VERSION ""

NS_ :

BS_:

BU_: ACC SRS SMART NAVI AHU FCM EPS HDS SS30 METER CVT STR ENG ABS VSA
VAL_TABLE_ VSA_DTC_STORAGE_STATUS 1 "DTC Stored(History or Current)" 0 "DTC Not Stored" ;
VAL_TABLE_ VSA_ABS_DISABLE_EDR 1 "ABS故障中" ;
VAL_TABLE_ VSA_STABILITY_CTRL1_DISABLE_EDR 1 "STABILITY CONTROL1制御のうち、少なくとも１つ禁止しているとき" 0 "STABILITY CONTROL1制御のうち、すべて禁止していないとき" ;
VAL_TABLE_ VSA_STABILITY_CTRL2_DISABLE_EDR 1 "STABILITY CONTROL2制御のうち、少なくとも１つ禁止しているとき" 0 "STABILITY CONTROL2制御のうち、すべて禁止していないとき" ;
VAL_TABLE_ VSA_VSA_EQUIPPED_EDR 1 "VSA装備あり" 0 "VSA装備なし(ABS装備)" ;
VAL_TABLE_ VSA_ABS_ACT_EDR 1 "ABS作動中" ;
VAL_TABLE_ VSA_STABILITY_CTRL_ACT_EDR 1 "STABILITY CONTROL作動中" ;
VAL_TABLE_ VSA_VSA_OFF_STATUS_EDR 1 "VSA OFF 中" ;
VAL_TABLE_ VSA_L_MODE_ABS_EBD 1 "ABS,EBD L-MODE中" ;
VAL_TABLE_ ENG_STRNNEND 1 "完爆状態" ;
VAL_TABLE_ ENG_SW_STATUS_SCS 1 "SCSスイッチオン" ;
VAL_TABLE_ SS30_REQ_PREBRAKE 1 "予圧要求" ;
VAL_TABLE_ SS30_REQ_BRAKE 1 "減速要求" ;
VAL_TABLE_ SS30_REQ_BRAKEHOLD 1 "ブレーキ保持要求" ;
VAL_TABLE_ SS30_STATUS_FAIL 1 "SS30故障" ;
VAL_TABLE_ METER_SW_STATUS_PARK_BRAKE 1 "パーキングブレーキ スイッチ オン" ;
VAL_TABLE_ METER_SW_STATUS_BRAKE_FLUID 1 "ブレーキフルード レベル スイッチ オン" ;
VAL_TABLE_ METER_SW_STATUS_VSA_OFF 1 "VSA-オフ スイッチ オン  " ;
VAL_TABLE_ CVT_REFUSE_VSA_CONTROL 1 "VSA制御を拒絶するCVT故障発生中" ;
VAL_TABLE_ CVT_GEAR_POSITION_IND_CVT 15 "Lレンジ制御中" 8 "8th" 7 "7th" 6 "6th" 5 "5th" 4 "4th" 3 "3rd" 2 "2nd" 1 "1st" 0 "オフ" ;
VAL_TABLE_ CVT_SHFT_IN_PARKING 1 "パーキング" ;
VAL_TABLE_ CVT_SHFT_IN_REVERSE 1 "リバース" ;
VAL_TABLE_ CVT_SHFT_IN_NEUTRAL 1 "ニュートラル" ;
VAL_TABLE_ CVT_SHFT_IN_D 1 "'D'" ;
VAL_TABLE_ CVT_SHFT_IN_S 1 "'S'" ;
VAL_TABLE_ CVT_SHFT_IN_L 1 "'L'" ;
VAL_TABLE_ ENG_IS_PRE_PROGRESS 1 "アイドルストップ実施予告からアイドルストップ復帰予告までを示す" ;
VAL_TABLE_ ENG_IS_PRE_RESTART 1 "アイドルストップ復帰予告を示す" ;
VAL_TABLE_ ENG_IS_PROGRESS 1 "アイドルストップ制御開始および進行中を示す" ;
VAL_TABLE_ ENG_CRUISE_STATUS_CRUISE_LMP 1 "クルーズ制御ランプ点灯" ;
VAL_TABLE_ CVT_CAS_ON 1 "VSAへのCAS_ON要求" ;
VAL_TABLE_ STR_ANGLE 32767 "故障時（Invalid）" 7560 "+756[deg]" 0 "0[deg]" 57976 "-756[deg]" ;
VAL_TABLE_ ENG_NEUTRAL_SENSOR_FAIL 1 "NEUTRAL SENSOR FAIL" ;
VAL_TABLE_ ENG_RECEIVE_ERROR_1AC 1 "受信エラーあり" ;
VAL_TABLE_ ENG_SHFT_IN_NEUTRAL 1 "シフトレバーがNEUTRALの位置にあるとき" ;
VAL_TABLE_ ENG_CLUTCH_SW_CC 0 "クラッチペダルが踏まれている時（SWがOFF）" 1 "クラッチペダルが踏まれていない時（SWがON）" ;
VAL_TABLE_ ENG_VSA_ACK1 2 "全気筒F/C" 1 "点火リタード" 0 "燃料/点火制御無し(THL制御のみ)" ;
VAL_TABLE_ ENG_VSA_PERMIT_PLUS_TRQ 1 "プラストルク許可中" ;
VAL_TABLE_ ENG_VSA_INHIBIT_VSA_CONTROL 1 "一時的なVSA F/C制御停止" ;
VAL_TABLE_ ENG_VSA_REFUSED_VSA_CONTROL 1 "VSA制御を拒絶する故障発生中" ;
VAL_TABLE_ VSA_COMMAND_CODE 5 "Reset of the Calibration" 3 "Calibration" ;
VAL_TABLE_ VSA_SPECIFY_CODE_SYS 1 "HMコード" 0 "SAEコード" ;
VAL_TABLE_ VSA_DTC_STORAGE 1 "格納" 0 "未格納" ;
VAL_TABLE_ VSA_MAEPS_REVERSE_F 1 "ﾘﾊﾞｰｽ状態" ;
VAL_TABLE_ VSA_SYSTEM_F 1 "VSAｼｽﾃﾑ故障" ;
VAL_TABLE_ VSA_REQ_CVT_TCS 1 "TCS作動許可状態" ;
VAL_TABLE_ VSA_REQ_CVT_PRS 1 "加圧中" ;
VAL_TABLE_ VSA_CONTROL_MODE_CVT 3 "予備" 2 "予備" 1 "TCS作動中" 0 "VSA制御可能状態" ;
VAL_TABLE_ VSA_ABS_STATUS_FR_ABS_EBD_ACT 1 "FR輪ABS、EBD作動中" ;
VAL_TABLE_ VSA_ABS_STATUS_FL_ABS_EBD_ACT 1 "FL輪ABS、EBD作動中" ;
VAL_TABLE_ VSA_ABS_STATUS_RR_ABS_EBD_ACT 1 "RR輪ABS、EBD作動中" ;
VAL_TABLE_ VSA_ABS_STATUS_RL_ABS_EBD_ACT 1 "RL輪ABS、EBD作動中" ;
VAL_TABLE_ VSA_FAIL_STEERING_SENSOR 1 "舵角センサ異常" ;
VAL_TABLE_ VSA_FAIL_YAW_RATE_SENSOR 1 "ヨーレイトセンサ異常" ;
VAL_TABLE_ VSA_FAIL_MC_PRESSURE_SENSOR_1B0 1 "M/C圧センサ異常" ;
VAL_TABLE_ VSA_ABS_FAIL_FR_VW_SENSOR 1 "車輪速センサFR輪異常" ;
VAL_TABLE_ VSA_ABS_FAIL_FL_VW_SENSOR 1 "車輪速センサFL輪異常" ;
VAL_TABLE_ VSA_ABS_FAIL_RR_VW_SENSOR 1 "車輪速センサRR輪異常" ;
VAL_TABLE_ VSA_ABS_FAIL_RL_VW_SENSOR 1 "車輪速センサRL輪異常" ;
VAL_TABLE_ VSA_ABS_INHBIT_VW_SENSOR 1 "車輪速センサ正常未確定" ;
VAL_TABLE_ VSA_ACC_INHIBIT_CVRS_BRAKE 1 "CVRSブレーキ一時禁止" ;
VAL_TABLE_ VSA_ACC_REFUSE_CVRS_BRAKE 1 "CVRSブレーキを拒絶する故障が発生" ;
VAL_TABLE_ VSA_VW_PULSE_CAPTURED 1 "車輪速パルスあり" ;
VAL_TABLE_ VSA_INHBIT_STEERING_SENSOR 1 "舵角センサ正常未確定" ;
VAL_TABLE_ VSA_INHBIT_YAW_RATE_SENSOR 1 "ヨーレートセンサ正常未確定" 0 "ヨーレートセンサ正常確定" ;
VAL_TABLE_ VSA_FAIL_BRAKERELAY 1 "BRAKEリレー　故障" ;
VAL_TABLE_ VSA_SS30_BRAKE_ACT 1 "SS30ブレーキ作動中" ;
VAL_TABLE_ VSA_REQ_MSR_PLUS_TRQ 1 "プラストルク要求中" ;
VAL_TABLE_ VSA_IS_SHIFT_INHIBIT_REQUEST 1 "アイドルストップ移行禁止要求中" 0 "通常時" ;
VAL_TABLE_ VSA_TRQ_CONTROL_MODE 3 "VSA/TCS禁止（VSA故障）" 2 "加速制御要求(エンジン制御が必要な場合にこの値をSETする)" 1 "MSR制御要求" 0 "VSA/TCS非制御中(ノーマル)" ;
VAL_TABLE_ VSA_SHIFT_REQ_1AC 3 "シフトDOWN要求" 2 "シフトUP要求" 1 "シフトホールド要求" 0 "VSAからのシフト制御要求無し(EATオリジナル制御)" ;
VAL_TABLE_ VSA_TRQ_DOWN_REQ_FUEL_CUT 2 "全気筒F/C＋点火リタード" 1 "点火リタード" 0 "燃料/点火制御無し(THL制御のみ)" ;
VAL_TABLE_ VSA_ABS_CTRL 1 "ABS制御中" ;
VAL_TABLE_ VSA_VSA_CTRL 1 "VSA制御中" ;
VAL_TABLE_ VSA_WARN_STATUS_HSA 1 "HSA warning is illuminated" ;
VAL_TABLE_ VSA_HSA_STATUS_ACT 1 "作動中" 0 "非作動中" ;
VAL_TABLE_ VSA_ESS_ACT4 1 "ABSﾌﾙｻｲｸﾘﾝｸﾞによるESS作動継続許可" 0 "ABSﾌﾙｻｲｸﾘﾝｸﾞによるESS作動継続禁止" ;
VAL_TABLE_ VSA_ESS_ACT3 1 "ABSﾌﾙｻｲｸﾘﾝｸﾞによるESS作動開始許可" 0 "ABSﾌﾙｻｲｸﾘﾝｸﾞによるESS作動開始禁止" ;
VAL_TABLE_ VSA_REWRITE_START 1 "VSA市場書換開始" ;
VAL_TABLE_ VSA_BUZZER_STATUS 1 "ブザーオン" 0 "ブザーオフ" ;
VAL_TABLE_ VSA_MID_REQUEST_VSA 1 "VSA MID拡大ワーニング表示許可" ;
VAL_TABLE_ VSA_LAMP_STATUS_VSA_OFF 1 "VSA　OFFﾗﾝﾌﾟ点灯" ;
VAL_TABLE_ VSA_WARN_STATUS_VSA 1 "VSA ウォーニングランプ点灯" ;
VAL_TABLE_ VSA_WARN_STATUS_ABS 1 "ABS ウォーニングランプ点灯" ;
VAL_TABLE_ VSA_WARN_STATUS_BRAKE 1 "BRAKE ウォーニングランプ点灯" ;
VAL_TABLE_ VSA_VSA_TCS_ACT 1 "VSA,TCS作動中" ;
VAL_TABLE_ VSA_ABS_EBD_ACT 1 "ABS,EBD作動中" ;
VAL_TABLE_ VSA_VSA_TCS_MIL 1 "VSA,TCS故障中" ;
VAL_TABLE_ VSA_ABS_EBD_MIL 1 "ABS,EBD故障中" ;
VAL_TABLE_ VSA_CASEN 1 "CAS作動許可" ;
VAL_TABLE_ VSA_CAS_ACT 1 "CAS作動中" ;
VAL_TABLE_ VSA_BA_ACT 1 "BA作動中" ;
VAL_TABLE_ VSA_MASTER_CYLINDER_PRESSURE 921 "19623.24kPa" 102 "0kPa" ;
VAL_TABLE_ VSA_FAIL_MC_PRESSURE_SENSOR 1 "マスタ圧センサ異常" ;
VAL_TABLE_ VSA_INHBIT_MC_PRESSURE_SENSOR 1 "マスタ圧センサ正常未確定" ;
VAL_TABLE_ VSA_ESS_ACT2 1 "減速度によるESS作動継続許可" 0 "減速度によるESS作動継続禁止" ;
VAL_TABLE_ VSA_ESS_ACT1 1 "減速度によるESS作動開始許可" 0 "減速度によるESS作動開始禁止" ;
VAL_TABLE_ VSA_SENSOR_START_UP 1 "起動中(センサ出力が保証できない時)" ;
VAL_TABLE_ VSA_SENSOR_ERR_MC 1 "マイコン及びそれに関わる診断が故障判定した時" ;
VAL_TABLE_ VSA_SENSOR_STATE_IG 1 "供給電圧(IG)がセンサの機能/性能を守れない時" ;
VAL_TABLE_ VSA_P_ERR_LON_G 1 "前後G加速度を故障判定した時" ;
VAL_TABLE_ VSA_P_ERR_LAT_G 1 "横G加速度を故障判定した時" ;
VAL_TABLE_ VSA_P_ERR_DEGC 1 "ヨーレート1温度データを故障判定した時" ;
VAL_TABLE_ VSA_P_ERR_YAW1 1 "ヨーレート1を故障判定した時" ;
VAL_TABLE_ VSA_T_ERR_LON_G 1 "前後G加速度が保証できない時" ;
VAL_TABLE_ VSA_T_ERR_LAT_G 1 "横G加速度が保証できない時" ;
VAL_TABLE_ VSA_T_ERR_DEGC 1 "ヨーレート1温度データが保証できない時" ;
VAL_TABLE_ VSA_T_ERR_YAW1 1 "ヨーレート1が保証できない時" ;
VAL_TABLE_ VSA_LON_G 1023 "24.5 [m/s2]" 512 "0 [m/s2]" 0 "-24.5 [m/s2]" ;
VAL_TABLE_ VSA_LAT_G 1023 "24.5 [m/s2]" 512 "0 [m/s2]" 0 "-24.5 [m/s2]" ;
VAL_TABLE_ VSA_DEGC 255 "+152 [℃]" 128 "+25 [℃]" 0 "-103 [℃]" ;
VAL_TABLE_ VSA_YAW_1 1023 "125.0 [°/s]" 512 "0 [°/s]" 0 "-125.0 [°/s]" ;

BO_ 3221225472 VECTOR__INDEPENDENT_SIG_MSG: 0 Vector__XXX
 SG_ ENG_CRUISE_STATUS_CRUISE_INH : 0|1@0+ (1,0) [0|1] "" Vector__XXX

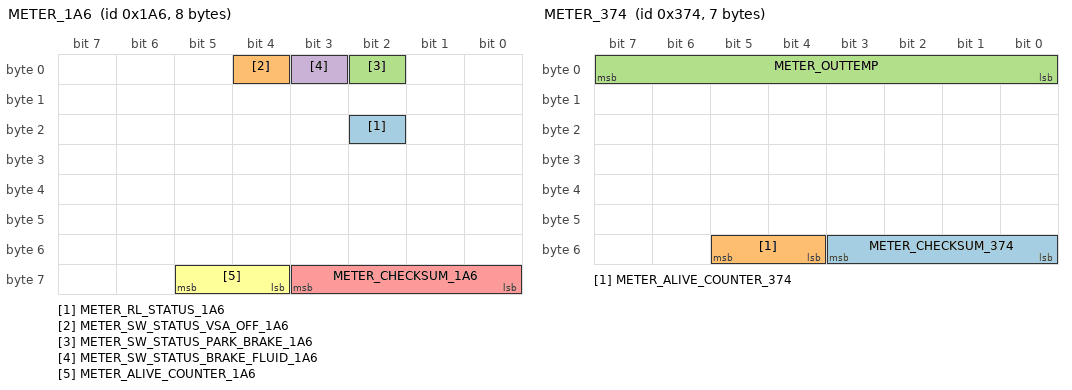
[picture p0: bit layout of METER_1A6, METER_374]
BO_ 422 METER_1A6: 8 Vector__XXX
 SG_ METER_RL_STATUS_1A6 : 18|1@0+ (1,0) [0|1] "" Vector__XXX
 SG_ METER_SW_STATUS_VSA_OFF_1A6 : 4|1@0+ (1,0) [0|1] "" Vector__XXX
 SG_ METER_SW_STATUS_PARK_BRAKE_1A6 : 2|1@0+ (1,0) [0|1] "" Vector__XXX
 SG_ METER_SW_STATUS_BRAKE_FLUID_1A6 : 3|1@0+ (1,0) [0|1] "" Vector__XXX
 SG_ METER_CHECKSUM_1A6 : 59|4@0+ (1,0) [0|15] "" Vector__XXX
 SG_ METER_ALIVE_COUNTER_1A6 : 61|2@0+ (1,0) [0|3] "" Vector__XXX

BO_ 884 METER_374: 7 METER
 SG_ METER_CHECKSUM_374 : 51|4@0+ (1,0) [0|15] "" Vector__XXX
 SG_ METER_ALIVE_COUNTER_374 : 53|2@0+ (1,0) [0|3] "" Vector__XXX
 SG_ METER_OUTTEMP : 7|8@0+ (1,0) [0|255] ""  VSA

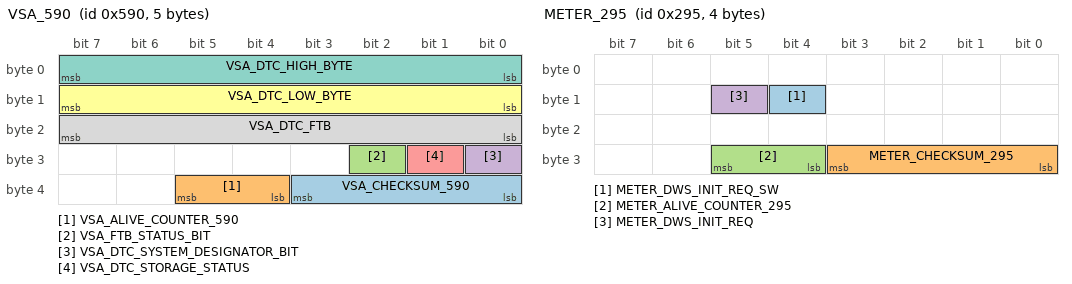
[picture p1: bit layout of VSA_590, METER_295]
BO_ 1424 VSA_590: 5 VSA
 SG_ VSA_CHECKSUM_590 : 35|4@0+ (1,0) [0|15] "" Vector__XXX
 SG_ VSA_ALIVE_COUNTER_590 : 37|2@0+ (1,0) [0|3] "" Vector__XXX
 SG_ VSA_FTB_STATUS_BIT : 26|1@0+ (1,0) [0|1] "" Vector__XXX
 SG_ VSA_DTC_SYSTEM_DESIGNATOR_BIT : 24|1@0+ (1,0) [0|1] "" Vector__XXX
 SG_ VSA_DTC_STORAGE_STATUS : 25|1@0+ (1,0) [0|1] "" Vector__XXX
 SG_ VSA_DTC_LOW_BYTE : 15|8@0+ (1,0) [0|255] "" Vector__XXX
 SG_ VSA_DTC_HIGH_BYTE : 7|8@0+ (1,0) [0|255] "" Vector__XXX
 SG_ VSA_DTC_FTB : 23|8@0+ (1,0) [0|255] "" Vector__XXX

BO_ 661 METER_295: 4 METER
 SG_ METER_DWS_INIT_REQ_SW : 12|1@0+ (1,0) [0|1] "" Vector__XXX
 SG_ METER_CHECKSUM_295 : 27|4@0+ (1,0) [0|15] "" Vector__XXX
 SG_ METER_ALIVE_COUNTER_295 : 29|2@0+ (1,0) [0|3] "" Vector__XXX
 SG_ METER_DWS_INIT_REQ : 13|1@0+ (1,0) [0|1] ""  VSA

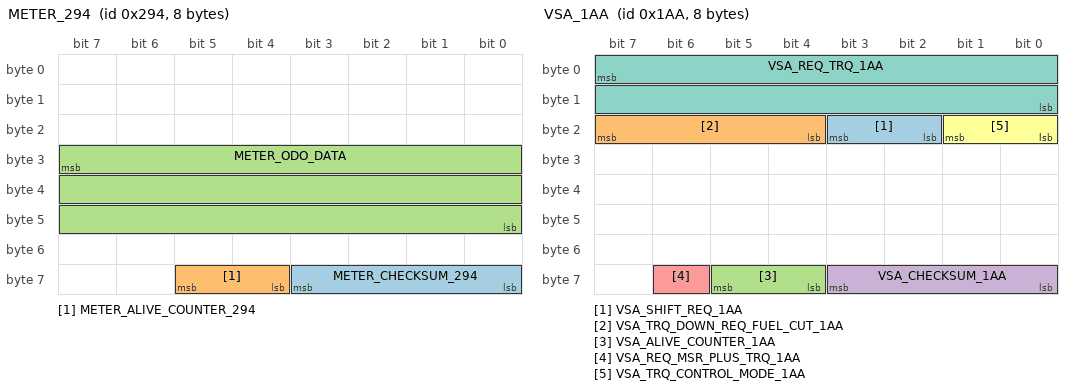
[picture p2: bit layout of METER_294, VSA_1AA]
BO_ 660 METER_294: 8 METER
 SG_ METER_CHECKSUM_294 : 59|4@0+ (1,0) [0|15] "" Vector__XXX
 SG_ METER_ALIVE_COUNTER_294 : 61|2@0+ (1,0) [0|3] "" Vector__XXX
 SG_ METER_ODO_DATA : 31|24@0+ (1,0) [0|16777215] "km"  VSA

BO_ 426 VSA_1AA: 8 Vector__XXX
 SG_ VSA_SHIFT_REQ_1AA : 19|2@0+ (1,0) [0|3] "" Vector__XXX
 SG_ VSA_TRQ_DOWN_REQ_FUEL_CUT_1AA : 23|4@0+ (1,0) [0|15] "" Vector__XXX
 SG_ VSA_ALIVE_COUNTER_1AA : 61|2@0+ (1,0) [0|3] "" Vector__XXX
 SG_ VSA_CHECKSUM_1AA : 59|4@0+ (1,0) [0|15] "" Vector__XXX
 SG_ VSA_REQ_MSR_PLUS_TRQ_1AA : 62|1@0+ (1,0) [0|1] "" Vector__XXX
 SG_ VSA_TRQ_CONTROL_MODE_1AA : 17|2@0+ (1,0) [0|3] "" Vector__XXX
 SG_ VSA_REQ_TRQ_1AA : 7|16@0- (0.2,0) [-6553.6|6553.4] "Nm" Vector__XXX

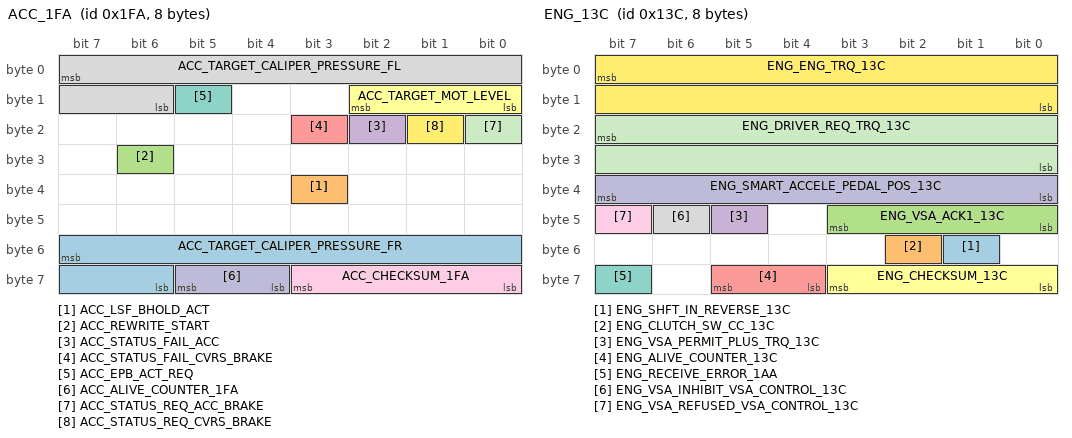
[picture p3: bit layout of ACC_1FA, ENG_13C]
BO_ 506 ACC_1FA: 8 ACC
 SG_ ACC_TARGET_CALIPER_PRESSURE_FR : 55|10@0+ (12.5,0) [0|12787.5] "kPa" Vector__XXX
 SG_ ACC_LSF_BHOLD_ACT : 35|1@0+ (1,0) [0|1] "" Vector__XXX
 SG_ ACC_REWRITE_START : 30|1@0+ (1,0) [0|1] "" Vector__XXX
 SG_ ACC_STATUS_FAIL_ACC : 18|1@0+ (1,0) [0|1] "" Vector__XXX
 SG_ ACC_STATUS_FAIL_CVRS_BRAKE : 19|1@0+ (1,0) [0|1] "" Vector__XXX
 SG_ ACC_TARGET_MOT_LEVEL : 10|3@0+ (1,0) [0|7] "" Vector__XXX
 SG_ ACC_EPB_ACT_REQ : 13|1@0+ (1,0) [0|1] "" Vector__XXX
 SG_ ACC_TARGET_CALIPER_PRESSURE_FL : 7|10@0+ (12.5,0) [0|12787.5] "kPa" Vector__XXX
 SG_ ACC_CHECKSUM_1FA : 59|4@0+ (1,0) [0|15] "" Vector__XXX
 SG_ ACC_ALIVE_COUNTER_1FA : 61|2@0+ (1,0) [0|3] "" Vector__XXX
 SG_ ACC_STATUS_REQ_ACC_BRAKE : 16|1@0+ (1,0) [0|1] "" Vector__XXX
 SG_ ACC_STATUS_REQ_CVRS_BRAKE : 17|1@0+ (1,0) [0|1] ""  VSA

BO_ 316 ENG_13C: 8 Vector__XXX
 SG_ ENG_SHFT_IN_REVERSE_13C : 49|1@0+ (1,0) [0|1] "" Vector__XXX
 SG_ ENG_CLUTCH_SW_CC_13C : 50|1@0+ (1,0) [0|1] "" Vector__XXX
 SG_ ENG_VSA_ACK1_13C : 43|4@0+ (1,0) [0|15] "" Vector__XXX
 SG_ ENG_VSA_PERMIT_PLUS_TRQ_13C : 45|1@0+ (1,0) [0|1] "" Vector__XXX
 SG_ ENG_ALIVE_COUNTER_13C : 61|2@0+ (1,0) [0|3] "" Vector__XXX
 SG_ ENG_CHECKSUM_13C : 59|4@0+ (1,0) [0|15] "" Vector__XXX
 SG_ ENG_RECEIVE_ERROR_1AA : 63|1@0+ (1,0) [0|1] "" Vector__XXX
 SG_ ENG_VSA_INHIBIT_VSA_CONTROL_13C : 46|1@0+ (1,0) [0|1] "" Vector__XXX
 SG_ ENG_VSA_REFUSED_VSA_CONTROL_13C : 47|1@0+ (1,0) [0|1] "" Vector__XXX
 SG_ ENG_SMART_ACCELE_PEDAL_POS_13C : 39|8@0+ (0.39215686275,0) [0|100] "%" Vector__XXX
 SG_ ENG_DRIVER_REQ_TRQ_13C : 23|16@0- (0.2,0) [-6553.6|6553.4] "Nm" Vector__XXX
 SG_ ENG_ENG_TRQ_13C : 7|16@0- (0.2,0) [-6553.6|6553.4] "Nm" Vector__XXX

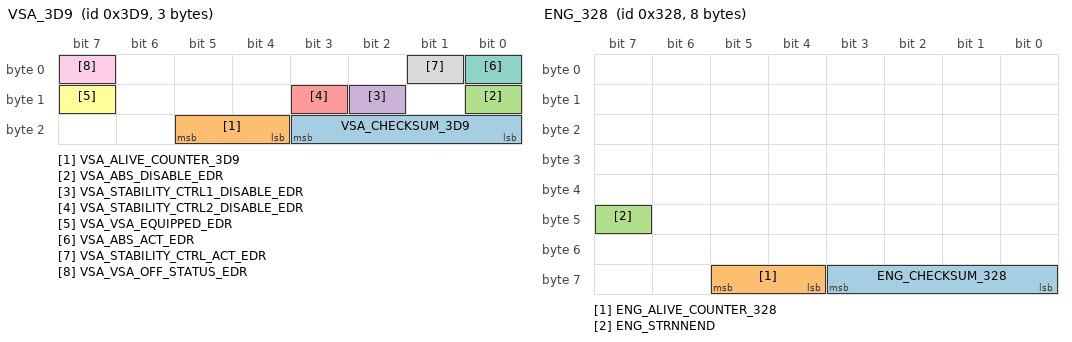
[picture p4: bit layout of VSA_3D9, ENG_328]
BO_ 985 VSA_3D9: 3 VSA
 SG_ VSA_CHECKSUM_3D9 : 19|4@0+ (1,0) [0|15] ""  SRS
 SG_ VSA_ALIVE_COUNTER_3D9 : 21|2@0+ (1,0) [0|3] ""  SRS
 SG_ VSA_ABS_DISABLE_EDR : 8|1@0+ (1,0) [0|1] ""  SRS
 SG_ VSA_STABILITY_CTRL1_DISABLE_EDR : 10|1@0+ (1,0) [0|1] ""  SRS
 SG_ VSA_STABILITY_CTRL2_DISABLE_EDR : 11|1@0+ (1,0) [0|1] ""  SRS
 SG_ VSA_VSA_EQUIPPED_EDR : 15|1@0+ (1,0) [0|1] ""  SRS
 SG_ VSA_ABS_ACT_EDR : 0|1@0+ (1,0) [0|1] ""  SRS
 SG_ VSA_STABILITY_CTRL_ACT_EDR : 1|1@0+ (1,0) [0|1] ""  SRS
 SG_ VSA_VSA_OFF_STATUS_EDR : 7|1@0+ (1,0) [0|1] ""  SRS

BO_ 2564550641 HDS_18DBEFF1: 8 HDS
 SG_ HDS_HDC_CAN : 7|64@0+ (1,0) [0|1.8446744074E+019] ""  VSA,NAVI,METER,ENG,CVT,AHU

BO_ 808 ENG_328: 8 ENG
 SG_ ENG_CHECKSUM_328 : 59|4@0+ (1,0) [0|15] ""  VSA,SMART,METER,EPS
 SG_ ENG_ALIVE_COUNTER_328 : 61|2@0+ (1,0) [0|3] ""  VSA,SMART,METER,EPS
 SG_ ENG_STRNNEND : 47|1@0+ (1,0) [0|1] ""  VSA,SMART,METER,EPS

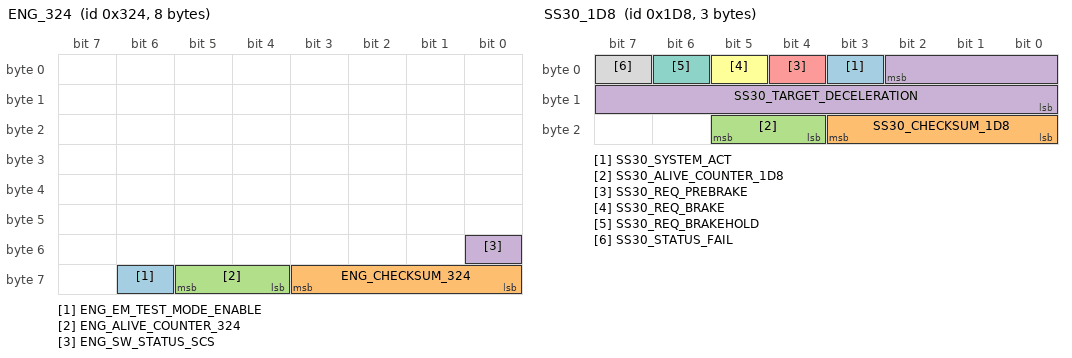
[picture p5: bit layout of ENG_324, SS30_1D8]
BO_ 804 ENG_324: 8 ENG
 SG_ ENG_EM_TEST_MODE_ENABLE : 62|1@0+ (1,0) [0|1] "" Vector__XXX
 SG_ ENG_CHECKSUM_324 : 59|4@0+ (1,0) [0|15] ""  VSA,SS30,SRS,METER,FCM,EPS,ABS
 SG_ ENG_ALIVE_COUNTER_324 : 61|2@0+ (1,0) [0|3] ""  VSA,SS30,SRS,METER,FCM,EPS,ABS
 SG_ ENG_SW_STATUS_SCS : 48|1@0+ (1,0) [0|1] ""  VSA,SS30,SRS,METER,EPS,ABS

BO_ 472 SS30_1D8: 3 SS30
 SG_ SS30_SYSTEM_ACT : 3|1@0+ (1,0) [0|1] "" Vector__XXX
 SG_ SS30_CHECKSUM_1D8 : 19|4@0+ (1,0) [0|15] "" Vector__XXX
 SG_ SS30_ALIVE_COUNTER_1D8 : 21|2@0+ (1,0) [0|3] "" Vector__XXX
 SG_ SS30_TARGET_DECELERATION : 2|11@0- (0.01,0) [-10.24|10.23] "m/s2" Vector__XXX
 SG_ SS30_REQ_PREBRAKE : 4|1@0+ (1,0) [0|1] ""  VSA
 SG_ SS30_REQ_BRAKE : 5|1@0+ (1,0) [0|1] ""  VSA
 SG_ SS30_REQ_BRAKEHOLD : 6|1@0+ (1,0) [0|1] "" Vector__XXX
 SG_ SS30_STATUS_FAIL : 7|1@0+ (1,0) [0|1] "" Vector__XXX

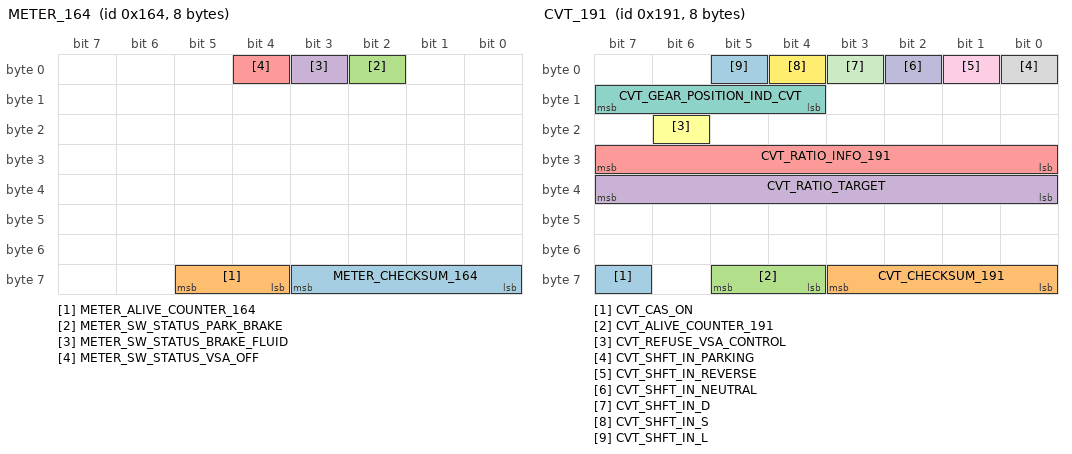
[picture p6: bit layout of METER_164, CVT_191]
BO_ 356 METER_164: 8 METER
 SG_ METER_CHECKSUM_164 : 59|4@0+ (1,0) [0|15] ""  VSA,SRS,ENG
 SG_ METER_ALIVE_COUNTER_164 : 61|2@0+ (1,0) [0|3] ""  VSA,SRS,ENG
 SG_ METER_SW_STATUS_PARK_BRAKE : 2|1@0+ (1,0) [0|1] ""  VSA,SRS
 SG_ METER_SW_STATUS_BRAKE_FLUID : 3|1@0+ (1,0) [0|1] ""  VSA
 SG_ METER_SW_STATUS_VSA_OFF : 4|1@0+ (1,0) [0|1] ""  VSA

BO_ 401 CVT_191: 8 CVT
 SG_ CVT_CAS_ON : 63|1@0+ (1,0) [0|1] "" Vector__XXX
 SG_ CVT_CHECKSUM_191 : 59|4@0+ (1,0) [0|15] ""  VSA,METER,FCM,EPS
 SG_ CVT_ALIVE_COUNTER_191 : 61|2@0+ (1,0) [0|3] ""  VSA,METER,FCM,EPS
 SG_ CVT_RATIO_TARGET : 39|8@0+ (0.015625,0) [0|3.984375] ""  VSA
 SG_ CVT_RATIO_INFO_191 : 31|8@0+ (0.015625,0) [0|3.984375] ""  VSA
 SG_ CVT_REFUSE_VSA_CONTROL : 22|1@0+ (1,0) [0|1] ""  VSA
 SG_ CVT_GEAR_POSITION_IND_CVT : 15|4@0+ (1,0) [0|15] ""  VSA,METER
 SG_ CVT_SHFT_IN_PARKING : 0|1@0+ (1,0) [0|1] ""  VSA,METER,EPS
 SG_ CVT_SHFT_IN_REVERSE : 1|1@0+ (1,0) [0|1] ""  VSA,METER
 SG_ CVT_SHFT_IN_NEUTRAL : 2|1@0+ (1,0) [0|1] ""  VSA,METER
 SG_ CVT_SHFT_IN_D : 3|1@0+ (1,0) [0|1] ""  VSA
 SG_ CVT_SHFT_IN_S : 4|1@0+ (1,0) [0|1] ""  VSA,METER
 SG_ CVT_SHFT_IN_L : 5|1@0+ (1,0) [0|1] ""  VSA,METER

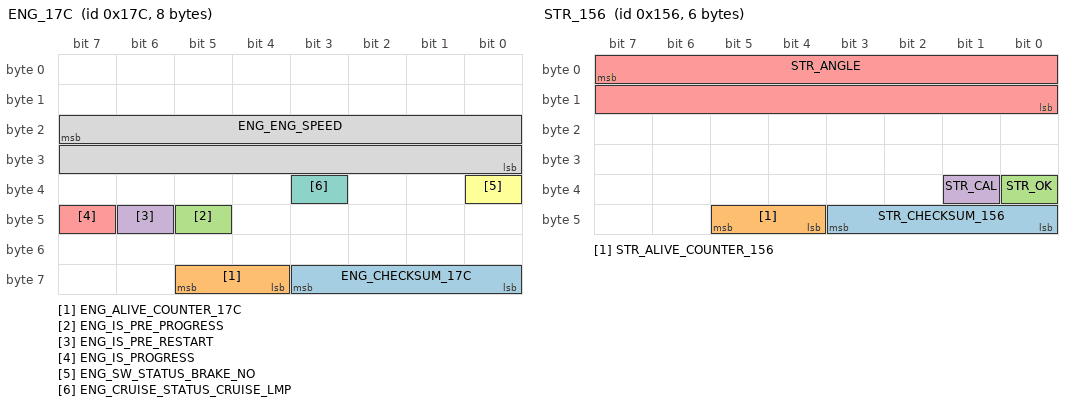
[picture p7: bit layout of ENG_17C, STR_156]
BO_ 380 ENG_17C: 8 ENG
 SG_ ENG_CHECKSUM_17C : 59|4@0+ (1,0) [0|15] ""  VSA,SS30,SRS,SMART,METER,FCM,EPS
 SG_ ENG_ALIVE_COUNTER_17C : 61|2@0+ (1,0) [0|3] ""  VSA,SS30,SRS,SMART,METER,FCM,EPS
 SG_ ENG_IS_PRE_PROGRESS : 45|1@0+ (1,0) [0|1] ""  VSA,EPS
 SG_ ENG_IS_PRE_RESTART : 46|1@0+ (1,0) [0|1] ""  VSA,SMART,METER,EPS
 SG_ ENG_IS_PROGRESS : 47|1@0+ (1,0) [0|1] ""  VSA,SMART,METER,EPS
 SG_ ENG_SW_STATUS_BRAKE_NO : 32|1@0+ (1,0) [0|1] ""  VSA,SRS,NAVI,AHU
 SG_ ENG_CRUISE_STATUS_CRUISE_LMP : 35|1@0+ (1,0) [0|1] ""  VSA,METER
 SG_ ENG_ENG_SPEED : 23|16@0+ (1,0) [0|65535] "rpm"  VSA,SRS,NAVI,EPS,AHU

BO_ 342 STR_156: 6 STR
 SG_ STR_CHECKSUM_156 : 43|4@0+ (1,0) [0|15] ""  VSA,SS30,SRS,METER,FCM,EPS
 SG_ STR_ALIVE_COUNTER_156 : 45|2@0+ (1,0) [0|3] ""  VSA,SS30,SRS,METER,FCM,EPS
 SG_ STR_OK : 32|1@0+ (1,0) [0|1] ""  VSA,SS30,SRS,METER,EPS
 SG_ STR_CAL : 33|1@0+ (1,0) [0|1] ""  VSA,SS30,METER,EPS
 SG_ STR_ANGLE : 7|16@0- (0.1,0) [-3276.8|3276.7] "deg"  VSA,SS30,SRS,METER,EPS

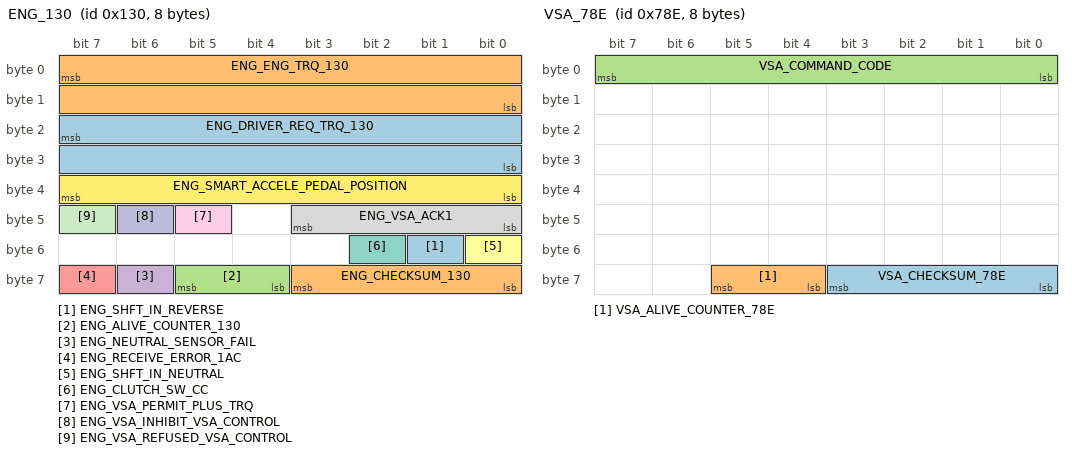
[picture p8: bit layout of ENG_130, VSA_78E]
BO_ 304 ENG_130: 8 ENG
 SG_ ENG_SHFT_IN_REVERSE : 49|1@0+ (1,0) [0|1] "" Vector__XXX
 SG_ ENG_CHECKSUM_130 : 59|4@0+ (1,0) [0|15] ""  VSA,SRS,EPS
 SG_ ENG_ALIVE_COUNTER_130 : 61|2@0+ (1,0) [0|3] ""  VSA,SRS,EPS
 SG_ ENG_NEUTRAL_SENSOR_FAIL : 62|1@0+ (1,0) [0|1] ""  VSA
 SG_ ENG_RECEIVE_ERROR_1AC : 63|1@0+ (1,0) [0|1] ""  VSA
 SG_ ENG_SHFT_IN_NEUTRAL : 48|1@0+ (1,0) [0|1] ""  VSA,EPS
 SG_ ENG_CLUTCH_SW_CC : 50|1@0+ (1,0) [0|1] ""  VSA
 SG_ ENG_VSA_ACK1 : 43|4@0+ (1,0) [0|15] ""  VSA
 SG_ ENG_VSA_PERMIT_PLUS_TRQ : 45|1@0+ (1,0) [0|1] ""  VSA
 SG_ ENG_VSA_INHIBIT_VSA_CONTROL : 46|1@0+ (1,0) [0|1] ""  VSA
 SG_ ENG_VSA_REFUSED_VSA_CONTROL : 47|1@0+ (1,0) [0|1] ""  VSA
 SG_ ENG_SMART_ACCELE_PEDAL_POSITION : 39|8@0+ (0.39215686275,0) [0|100] "%"  VSA,SRS
 SG_ ENG_DRIVER_REQ_TRQ_130 : 23|16@0- (1,0) [-32768|32767] "Nm"  VSA
 SG_ ENG_ENG_TRQ_130 : 7|16@0- (1,0) [-32768|32767] "Nm"  VSA

BO_ 1934 VSA_78E: 8 VSA
 SG_ VSA_CHECKSUM_78E : 59|4@0+ (1,0) [0|15] ""  STR
 SG_ VSA_ALIVE_COUNTER_78E : 61|2@0+ (1,0) [0|3] ""  STR
 SG_ VSA_COMMAND_CODE : 7|8@0+ (1,0) [0|255] ""  STR

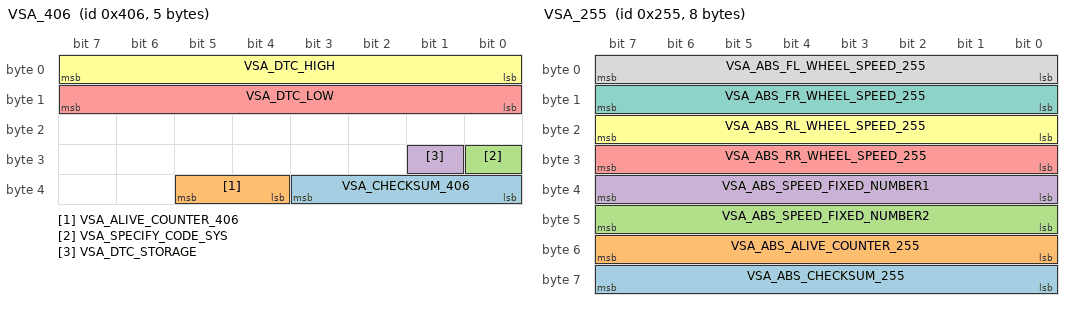
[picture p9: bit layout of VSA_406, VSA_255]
BO_ 1030 VSA_406: 5 VSA
 SG_ VSA_CHECKSUM_406 : 35|4@0+ (1,0) [0|15] "" Vector__XXX
 SG_ VSA_ALIVE_COUNTER_406 : 37|2@0+ (1,0) [0|3] "" Vector__XXX
 SG_ VSA_SPECIFY_CODE_SYS : 24|1@0+ (1,0) [0|1] "" Vector__XXX
 SG_ VSA_DTC_STORAGE : 25|1@0+ (1,0) [0|1] "" Vector__XXX
 SG_ VSA_DTC_LOW : 15|8@0+ (1,0) [0|255] ""  NAVI,AHU
 SG_ VSA_DTC_HIGH : 7|8@0+ (1,0) [0|255] ""  NAVI,AHU

BO_ 597 VSA_255: 8 ABS
 SG_ VSA_ABS_CHECKSUM_255 : 63|8@0+ (1,0) [0|255] ""  SMART,METER
 SG_ VSA_ABS_ALIVE_COUNTER_255 : 55|8@0+ (1,0) [0|255] ""  SMART,METER
 SG_ VSA_ABS_SPEED_FIXED_NUMBER2 : 47|8@0+ (1,0) [0|255] ""  SMART,METER
 SG_ VSA_ABS_SPEED_FIXED_NUMBER1 : 39|8@0+ (1,0) [0|255] ""  SMART,METER
 SG_ VSA_ABS_RR_WHEEL_SPEED_255 : 31|8@0+ (1,0) [0|255] "km/h"  SMART,METER
 SG_ VSA_ABS_RL_WHEEL_SPEED_255 : 23|8@0+ (1,0) [0|255] "km/h"  SMART,METER
 SG_ VSA_ABS_FR_WHEEL_SPEED_255 : 15|8@0+ (1,0) [0|255] "km/h"  SMART,METER
 SG_ VSA_ABS_FL_WHEEL_SPEED_255 : 7|8@0+ (1,0) [0|255] "km/h"  SMART,METER,ENG

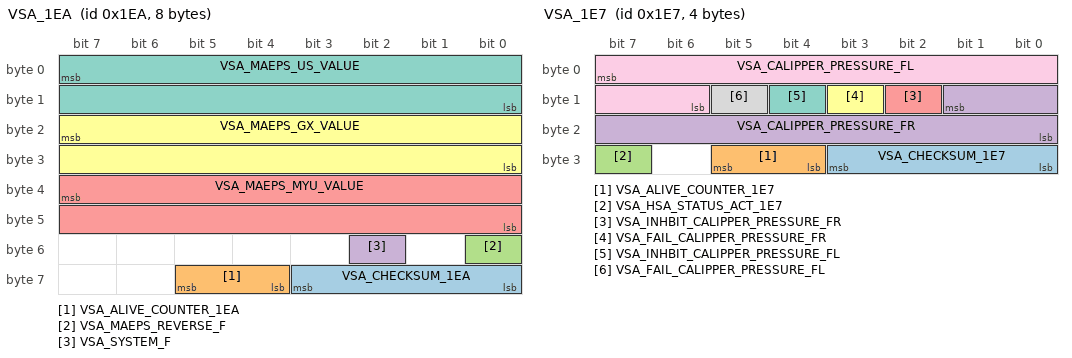
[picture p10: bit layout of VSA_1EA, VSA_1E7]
BO_ 490 VSA_1EA: 8 VSA
 SG_ VSA_CHECKSUM_1EA : 59|4@0+ (1,0) [0|15] ""  EPS
 SG_ VSA_ALIVE_COUNTER_1EA : 61|2@0+ (1,0) [0|3] ""  EPS
 SG_ VSA_MAEPS_REVERSE_F : 48|1@0+ (1,0) [0|1] ""  EPS
 SG_ VSA_SYSTEM_F : 50|1@0+ (1,0) [0|1] ""  EPS
 SG_ VSA_MAEPS_MYU_VALUE : 39|16@0- (3.90625E-005,0) [-1.28|1.2799609375] ""  EPS
 SG_ VSA_MAEPS_GX_VALUE : 23|16@0- (0.00015258789063,0) [-5|4.9998474121] "G"  EPS
 SG_ VSA_MAEPS_US_VALUE : 7|16@0- (0.0038146972656,0) [-125|124.9961853] "deg/s"  EPS

BO_ 487 VSA_1E7: 4 VSA
 SG_ VSA_CHECKSUM_1E7 : 27|4@0+ (1,0) [0|15] "" Vector__XXX
 SG_ VSA_ALIVE_COUNTER_1E7 : 29|2@0+ (1,0) [0|3] "" Vector__XXX
 SG_ VSA_HSA_STATUS_ACT_1E7 : 31|1@0+ (1,0) [0|1] "" Vector__XXX
 SG_ VSA_CALIPPER_PRESSURE_FR : 9|10@0+ (23.96,-2443.92) [-2443.92|22067.16] "kPa" Vector__XXX
 SG_ VSA_INHBIT_CALIPPER_PRESSURE_FR : 10|1@0+ (1,0) [0|1] "" Vector__XXX
 SG_ VSA_FAIL_CALIPPER_PRESSURE_FR : 11|1@0+ (1,0) [0|1] "" Vector__XXX
 SG_ VSA_INHBIT_CALIPPER_PRESSURE_FL : 12|1@0+ (1,0) [0|1] "" Vector__XXX
 SG_ VSA_FAIL_CALIPPER_PRESSURE_FL : 13|1@0+ (1,0) [0|1] "" Vector__XXX
 SG_ VSA_CALIPPER_PRESSURE_FL : 7|10@0+ (23.96,-2443.92) [-2443.92|22067.16] "kPa" Vector__XXX

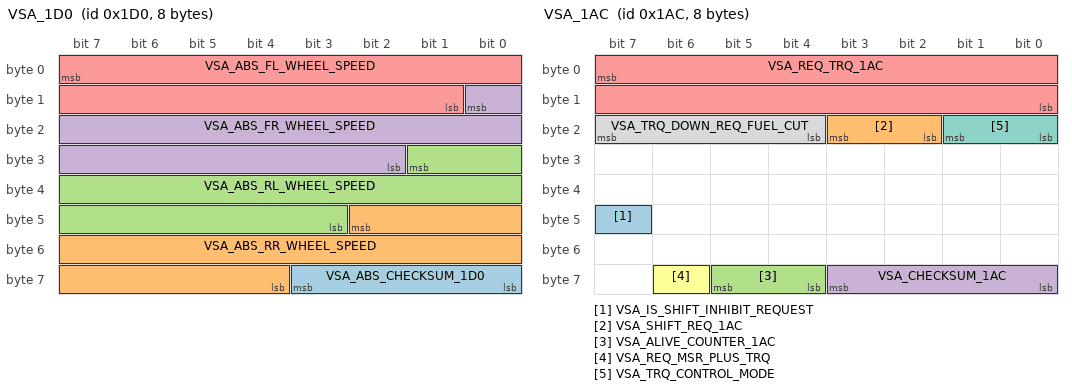
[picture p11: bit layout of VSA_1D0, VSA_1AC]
BO_ 464 VSA_1D0: 8 VSA
 SG_ VSA_ABS_CHECKSUM_1D0 : 59|4@0+ (1,0) [0|15] ""  SS30,EPS,ENG,CVT
 SG_ VSA_ABS_RR_WHEEL_SPEED : 42|15@0+ (0.01,0) [0|327.67] "km/h"  SS30,EPS,ENG,CVT
 SG_ VSA_ABS_RL_WHEEL_SPEED : 25|15@0+ (0.01,0) [0|327.67] "km/h"  SS30,EPS,ENG,CVT
 SG_ VSA_ABS_FR_WHEEL_SPEED : 8|15@0+ (0.01,0) [0|327.67] "km/h"  SS30,EPS,ENG,CVT
 SG_ VSA_ABS_FL_WHEEL_SPEED : 7|15@0+ (0.01,0) [0|327.67] "km/h"  SS30,EPS,ENG,CVT

BO_ 432 VSA_1B0: 7 VSA
 SG_ VSA_ACC_REFUSE_ACC_BRAKE : 9|1@0+ (1,0) [0|1] "" Vector__XXX
 SG_ VSA_ACC_INHIBIT_ACC_BRAKE : 8|1@0+ (1,0) [0|1] "" Vector__XXX
 SG_ VSA_ABS_VW_SENSOR_START_UP : 15|1@0+ (1,0) [0|1] "" Vector__XXX
 SG_ VSA_INHIBIT_BRAKERELAY : 5|1@0+ (1,0) [0|1] "" Vector__XXX
 SG_ VSA_INHBIT_LAT_G_SENSOR : 1|1@0+ (1,0) [0|1] "" Vector__XXX
 SG_ VSA_FAIL_LAT_G_SENSOR : 3|1@0+ (1,0) [0|1] "" Vector__XXX
 SG_ VSA_ACT_BRAKERELAY : 0|1@0+ (1,0) [0|1] "" Vector__XXX
 SG_ VSA_CHECKSUM_1B0 : 51|4@0+ (1,0) [0|15] ""  SS30,METER,FCM,EPS,CVT
 SG_ VSA_ALIVE_COUNTER_1B0 : 53|2@0+ (1,0) [0|3] ""  SS30,METER,FCM,EPS,CVT
 SG_ VSA_REQ_CVT_TCS : 40|1@0+ (1,0) [0|1] ""  CVT
 SG_ VSA_REQ_CVT_PRS : 41|1@0+ (1,0) [0|1] ""  CVT
 SG_ VSA_CONTROL_MODE_CVT : 43|2@0+ (1,0) [0|3] ""  CVT
 SG_ VSA_ABS_STATUS_FR_ABS_EBD_ACT : 44|1@0+ (1,0) [0|1] "" Vector__XXX
 SG_ VSA_ABS_STATUS_FL_ABS_EBD_ACT : 45|1@0+ (1,0) [0|1] "" Vector__XXX
 SG_ VSA_ABS_STATUS_RR_ABS_EBD_ACT : 46|1@0+ (1,0) [0|1] "" Vector__XXX
 SG_ VSA_ABS_STATUS_RL_ABS_EBD_ACT : 47|1@0+ (1,0) [0|1] "" Vector__XXX
 SG_ VSA_FAIL_STEERING_SENSOR : 32|1@0+ (1,0) [0|1] "" Vector__XXX
 SG_ VSA_FAIL_YAW_RATE_SENSOR : 33|1@0+ (1,0) [0|1] ""  SS30
 SG_ VSA_FAIL_MC_PRESSURE_SENSOR_1B0 : 34|1@0+ (1,0) [0|1] "" Vector__XXX
 SG_ VSA_ABS_FAIL_FR_VW_SENSOR : 35|1@0+ (1,0) [0|1] ""  SS30,EPS,CVT
 SG_ VSA_ABS_FAIL_FL_VW_SENSOR : 36|1@0+ (1,0) [0|1] ""  SS30,EPS,CVT
 SG_ VSA_ABS_FAIL_RR_VW_SENSOR : 37|1@0+ (1,0) [0|1] ""  SS30,EPS,CVT
 SG_ VSA_ABS_FAIL_RL_VW_SENSOR : 38|1@0+ (1,0) [0|1] ""  SS30,EPS,CVT
 SG_ VSA_ABS_INHBIT_VW_SENSOR : 39|1@0+ (1,0) [0|1] ""  SS30,EPS
 SG_ VSA_STEERING_ANGLE : 23|16@0- (1,0) [-32768|32767] "deg" Vector__XXX
 SG_ VSA_ACC_INHIBIT_CVRS_BRAKE : 10|1@0+ (1,0) [0|1] ""  SS30
 SG_ VSA_INHBIT_STEERING_SENSOR : 13|1@0+ (1,0) [0|1] "" Vector__XXX
 SG_ VSA_ACC_REFUSE_CVRS_BRAKE : 11|1@0+ (1,0) [0|1] ""  SS30
 SG_ VSA_VW_PULSE_CAPTURED : 12|1@0+ (1,0) [0|1] ""  SS30
 SG_ VSA_INHBIT_YAW_RATE_SENSOR : 14|1@0+ (1,0) [0|1] "-"  SS30
 SG_ VSA_FAIL_BRAKERELAY : 6|1@0+ (1,0) [0|1] ""  SS30
 SG_ VSA_SS30_BRAKE_ACT : 7|1@0+ (1,0) [0|1] ""  SS30

BO_ 428 VSA_1AC: 8 VSA
 SG_ VSA_IS_SHIFT_INHIBIT_REQUEST : 47|1@0+ (1,0) [0|1] "" Vector__XXX
 SG_ VSA_SHIFT_REQ_1AC : 19|2@0+ (1,0) [0|3] "" Vector__XXX
 SG_ VSA_ALIVE_COUNTER_1AC : 61|2@0+ (1,0) [0|3] "" Vector__XXX
 SG_ VSA_CHECKSUM_1AC : 59|4@0+ (1,0) [0|15] "" Vector__XXX
 SG_ VSA_REQ_TRQ_1AC : 7|16@0- (1,0) [-32768|32767] "Nm" Vector__XXX
 SG_ VSA_REQ_MSR_PLUS_TRQ : 62|1@0+ (1,0) [0|1] "" Vector__XXX
 SG_ VSA_TRQ_CONTROL_MODE : 17|2@0+ (1,0) [0|3] "" Vector__XXX
 SG_ VSA_TRQ_DOWN_REQ_FUEL_CUT : 23|4@0+ (1,0) [0|15] "" Vector__XXX

BO_ 420 VSA_1A4: 8 VSA
 SG_ VSA_ACC_BRAKE_ACT : 23|1@0+ (1,0) [0|1] "" Vector__XXX
 SG_ VSA_WARN_STATUS_PUNCTURE : 25|1@0+ (1,0) [0|1] "" Vector__XXX
 SG_ VSA_WARN_STATUS_DWS : 26|1@0+ (1,0) [0|1] "" Vector__XXX
 SG_ VSA_ANSWER_DWS_INIT_REQ : 24|1@0+ (1,0) [0|1] "" Vector__XXX
 SG_ VSA_L_MODE_ABS_EBD : 32|1@0+ (1,0) [0|1] "" Vector__XXX
 SG_ VSA_CHECKSUM_1A4 : 59|4@0+ (1,0) [0|15] ""  SS30,SMART,METER,FCM,EPS,ENG,CVT
 SG_ VSA_ALIVE_COUNTER_1A4 : 61|2@0+ (1,0) [0|3] ""  SS30,SMART,METER,FCM,EPS,ENG,CVT
 SG_ VSA_ABS_CTRL : 62|1@0+ (1,0) [0|1] ""  SS30
 SG_ VSA_VSA_CTRL : 63|1@0+ (1,0) [0|1] ""  SS30
 SG_ VSA_WARN_STATUS_HSA : 48|1@0+ (1,0) [0|1] ""  METER
 SG_ VSA_HSA_STATUS_ACT : 49|1@0+ (1,0) [0|1] "" Vector__XXX
 SG_ VSA_ESS_ACT4 : 50|1@0+ (1,0) [0|1] ""  METER
 SG_ VSA_ESS_ACT3 : 51|1@0+ (1,0) [0|1] ""  METER
 SG_ VSA_REWRITE_START : 34|1@0+ (1,0) [0|1] ""  SMART,EPS
 SG_ VSA_BUZZER_STATUS : 35|1@0+ (1,0) [0|1] ""  METER
 SG_ VSA_MID_REQUEST_VSA : 27|1@0+ (1,0) [0|1] ""  METER
 SG_ VSA_LAMP_STATUS_VSA_OFF : 28|1@0+ (1,0) [0|1] ""  METER
 SG_ VSA_WARN_STATUS_VSA : 29|1@0+ (1,0) [0|1] ""  METER
 SG_ VSA_WARN_STATUS_ABS : 30|1@0+ (1,0) [0|1] ""  METER,ENG,CVT
 SG_ VSA_WARN_STATUS_BRAKE : 31|1@0+ (1,0) [0|1] ""  METER
 SG_ VSA_VSA_TCS_ACT : 16|1@0+ (1,0) [0|1] ""  NAVI,EPS,ENG,CVT,AHU
 SG_ VSA_ABS_EBD_ACT : 17|1@0+ (1,0) [0|1] ""  NAVI,EPS,CVT,AHU
 SG_ VSA_VSA_TCS_MIL : 18|1@0+ (1,0) [0|1] "" Vector__XXX
 SG_ VSA_ABS_EBD_MIL : 19|1@0+ (1,0) [0|1] ""  SS30,ENG
 SG_ VSA_CASEN : 20|1@0+ (1,0) [0|1] ""  CVT
 SG_ VSA_CAS_ACT : 21|1@0+ (1,0) [0|1] ""  CVT
 SG_ VSA_BA_ACT : 22|1@0+ (1,0) [0|1] ""  SS30
 SG_ VSA_MASTER_CYLINDER_PRESSURE : 3|12@0+ (23.96,-2443.92) [-2443.92|95672.28] "kPa"  SS30,ENG
 SG_ VSA_FAIL_MC_PRESSURE_SENSOR : 4|1@0+ (1,0) [0|1] ""  SS30,ENG
 SG_ VSA_INHBIT_MC_PRESSURE_SENSOR : 5|1@0+ (1,0) [0|1] ""  SS30,ENG
 SG_ VSA_ESS_ACT2 : 6|1@0+ (1,0) [0|1] ""  METER
 SG_ VSA_ESS_ACT1 : 7|1@0+ (1,0) [0|1] ""  METER

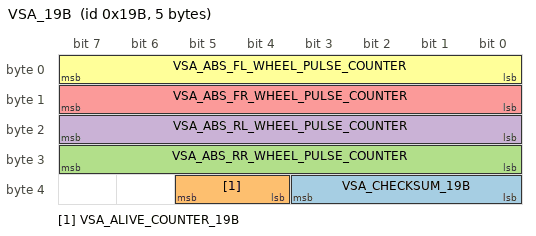
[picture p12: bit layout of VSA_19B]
BO_ 411 VSA_19B: 5 Vector__XXX
 SG_ VSA_CHECKSUM_19B : 35|4@0+ (1,0) [0|15] "" Vector__XXX
 SG_ VSA_ALIVE_COUNTER_19B : 37|2@0+ (1,0) [0|3] "" Vector__XXX
 SG_ VSA_ABS_RR_WHEEL_PULSE_COUNTER : 31|8@0+ (1,0) [0|255] "" Vector__XXX
 SG_ VSA_ABS_RL_WHEEL_PULSE_COUNTER : 23|8@0+ (1,0) [0|255] "" Vector__XXX
 SG_ VSA_ABS_FR_WHEEL_PULSE_COUNTER : 15|8@0+ (1,0) [0|255] "" Vector__XXX
 SG_ VSA_ABS_FL_WHEEL_PULSE_COUNTER : 7|8@0+ (1,0) [0|255] "" Vector__XXX

BO_ 145 VSA_091: 8 VSA
 SG_ VSA_CHECKSUM_091 : 59|4@0+ (1,0) [0|15] ""  SS30,FCM,EPS,CVT
 SG_ VSA_ALIVE_COUNTER_091 : 61|2@0+ (1,0) [0|3] ""  SS30,FCM,EPS,CVT
 SG_ VSA_SENSOR_START_UP : 63|1@0+ (1,0) [0|1] ""  SS30,EPS,CVT
 SG_ VSA_SENSOR_ERR_MC : 48|1@0+ (1,0) [0|1] ""  EPS,CVT
 SG_ VSA_SENSOR_STATE_IG : 49|1@0+ (1,0) [0|1] ""  EPS,CVT
 SG_ VSA_P_ERR_LON_G : 52|1@0+ (1,0) [0|1] ""  CVT
 SG_ VSA_P_ERR_LAT_G : 53|1@0+ (1,0) [0|1] ""  EPS
 SG_ VSA_P_ERR_DEGC : 54|1@0+ (1,0) [0|1] "" Vector__XXX
 SG_ VSA_P_ERR_YAW1 : 55|1@0+ (1,0) [0|1] ""  EPS
 SG_ VSA_T_ERR_LON_G : 44|1@0+ (1,0) [0|1] ""  CVT
 SG_ VSA_T_ERR_LAT_G : 45|1@0+ (1,0) [0|1] ""  EPS
 SG_ VSA_T_ERR_DEGC : 46|1@0+ (1,0) [0|1] "" Vector__XXX
 SG_ VSA_T_ERR_YAW1 : 47|1@0+ (1,0) [0|1] ""  EPS
 SG_ VSA_LON_G : 25|10@0+ (0.047851563,-24.5) [-24.5|24.452148949] ""  CVT
 SG_ VSA_LAT_G : 19|10@0+ (0.047851563,-24.5) [-24.5|24.452148949] ""  SS30,EPS
 SG_ VSA_DEGC : 13|8@0+ (1,-103) [-103|152] "" Vector__XXX
 SG_ VSA_YAW_1 : 7|10@0+ (0.244140625,-125) [-125|124.75585938] ""  SS30,EPS

BO_TX_BU_ 597 : VSA,ABS;

CM_ BO_ 3221225472 "This is a message for not used signals, created by Vector CANdb++ DBC OLE DB Provider.";
BA_DEF_ SG_  "ValueTableE" STRING ;
BA_DEF_ SG_  "CommentTxJ" STRING ;
BA_DEF_ SG_  "DescriptionE" STRING ;
BA_DEF_ SG_  "DescriptionJ" STRING ;
BA_DEF_ SG_  "GenSigStartValue" INT 0 3000;
BA_DEF_ BO_  "PS" ENUM  "+B","ACC","IG1","IG2","*","vector_leerstring";
BA_DEF_ BO_  "FrameType" INT 0 2;
BA_DEF_ SG_  "GenSigSendType" ENUM  "Cyclic","OnWrite","OnWriteWithRepetition","OnChange","OnChangeWithRepetition","IfActive","IfActiveWithRepetition","NoSigSendType";
BA_DEF_ BO_  "GenMsgCycleTime" INT 0 0;
BA_DEF_ BO_  "GenMsgSendType" ENUM  "Cyclic","not_used","not_used","not_used","not_used","Cyclic","not_used","IfActive","NoMsgSendType";
BA_DEF_  "DBName" STRING ;
BA_DEF_  "BusType" STRING ;
BA_DEF_DEF_  "ValueTableE" "";
BA_DEF_DEF_  "CommentTxJ" "";
BA_DEF_DEF_  "DescriptionE" "";
BA_DEF_DEF_  "DescriptionJ" "";
BA_DEF_DEF_  "GenSigStartValue" 0;
BA_DEF_DEF_  "PS" "";
BA_DEF_DEF_  "FrameType" 2;
BA_DEF_DEF_  "GenSigSendType" "Cyclic";
BA_DEF_DEF_  "GenMsgCycleTime" 0;
BA_DEF_DEF_  "GenMsgSendType" "NoMsgSendType";
BA_DEF_DEF_  "DBName" "";
BA_DEF_DEF_  "BusType" "CAN";
BA_ "DBName" "Honda";
BA_ "PS" BO_ 422 5;
BA_ "GenMsgCycleTime" BO_ 422 10;
BA_ "GenMsgSendType" BO_ 422 0;
BA_ "GenMsgSendType" BO_ 884 0;
BA_ "GenMsgCycleTime" BO_ 884 100;
BA_ "PS" BO_ 884 5;
BA_ "GenMsgSendType" BO_ 661 0;
BA_ "GenMsgCycleTime" BO_ 661 40;
BA_ "PS" BO_ 661 5;
BA_ "GenMsgSendType" BO_ 660 0;
BA_ "GenMsgCycleTime" BO_ 660 40;
BA_ "PS" BO_ 660 5;
BA_ "PS" BO_ 426 5;
BA_ "GenMsgCycleTime" BO_ 426 20;
BA_ "GenMsgSendType" BO_ 426 0;
BA_ "PS" BO_ 316 5;
BA_ "GenMsgCycleTime" BO_ 316 10;
BA_ "GenMsgSendType" BO_ 316 0;
BA_ "PS" BO_ 985 5;
BA_ "GenMsgCycleTime" BO_ 985 200;
BA_ "GenMsgSendType" BO_ 985 0;
BA_ "PS" BO_ 2564550641 5;
BA_ "GenMsgSendType" BO_ 2564550641 0;
BA_ "PS" BO_ 808 5;
BA_ "GenMsgCycleTime" BO_ 808 100;
BA_ "GenMsgSendType" BO_ 808 0;
BA_ "PS" BO_ 804 5;
BA_ "GenMsgCycleTime" BO_ 804 100;
BA_ "GenMsgSendType" BO_ 804 0;
BA_ "PS" BO_ 472 5;
BA_ "GenMsgCycleTime" BO_ 472 20;
BA_ "GenMsgSendType" BO_ 472 0;
BA_ "PS" BO_ 356 5;
BA_ "GenMsgCycleTime" BO_ 356 10;
BA_ "GenMsgSendType" BO_ 356 0;
BA_ "PS" BO_ 401 5;
BA_ "GenMsgCycleTime" BO_ 401 10;
BA_ "GenMsgSendType" BO_ 401 0;
BA_ "PS" BO_ 380 5;
BA_ "GenMsgCycleTime" BO_ 380 10;
BA_ "GenMsgSendType" BO_ 380 0;
BA_ "PS" BO_ 342 5;
BA_ "GenMsgCycleTime" BO_ 342 10;
BA_ "GenMsgSendType" BO_ 342 0;
BA_ "PS" BO_ 304 5;
BA_ "GenMsgCycleTime" BO_ 304 10;
BA_ "GenMsgSendType" BO_ 304 0;
BA_ "PS" BO_ 1934 5;
BA_ "GenMsgSendType" BO_ 1934 0;
BA_ "PS" BO_ 1030 5;
BA_ "GenMsgCycleTime" BO_ 1030 300;
BA_ "GenMsgSendType" BO_ 1030 0;
BA_ "PS" BO_ 597 5;
BA_ "GenMsgCycleTime" BO_ 597 40;
BA_ "GenMsgSendType" BO_ 597 0;
BA_ "PS" BO_ 490 5;
BA_ "GenMsgCycleTime" BO_ 490 20;
BA_ "GenMsgSendType" BO_ 490 0;
BA_ "PS" BO_ 464 5;
BA_ "GenMsgCycleTime" BO_ 464 20;
BA_ "GenMsgSendType" BO_ 464 0;
BA_ "PS" BO_ 432 5;
BA_ "GenMsgCycleTime" BO_ 432 20;
BA_ "GenMsgSendType" BO_ 432 0;
BA_ "PS" BO_ 428 5;
BA_ "GenMsgCycleTime" BO_ 428 20;
BA_ "GenMsgSendType" BO_ 428 0;
BA_ "PS" BO_ 420 5;
BA_ "GenMsgCycleTime" BO_ 420 20;
BA_ "GenMsgSendType" BO_ 420 0;
BA_ "GenMsgSendType" BO_ 411 0;
BA_ "GenMsgCycleTime" BO_ 411 10;
BA_ "PS" BO_ 411 5;
BA_ "PS" BO_ 145 5;
BA_ "GenMsgCycleTime" BO_ 145 10;
BA_ "GenMsgSendType" BO_ 145 0;
BA_ "DescriptionE" SG_ 3221225472 ENG_CRUISE_STATUS_CRUISE_INH "Indicates inhibition of cruise control.";
BA_ "DescriptionJ" SG_ 3221225472 ENG_CRUISE_STATUS_CRUISE_INH "クルーズ制御禁止を示す";
BA_ "ValueTableE" SG_ 422 METER_RL_STATUS_1A6 "1: Parking brake SW ON";
BA_ "ValueTableE" SG_ 422 METER_SW_STATUS_VSA_OFF_1A6 "1: VSA-off SW ON";
BA_ "ValueTableE" SG_ 422 METER_SW_STATUS_PARK_BRAKE_1A6 "1: Parking brake SW ON";
BA_ "ValueTableE" SG_ 422 METER_SW_STATUS_BRAKE_FLUID_1A6 "1: Brake fluid level SW ON";
BA_ "DescriptionE" SG_ 422 METER_ALIVE_COUNTER_1A6 "Incremented by 1 every time a packet is refreshed.

(0 to 3 ring counters)";
BA_ "DescriptionJ" SG_ 422 METER_ALIVE_COUNTER_1A6 "1パケット更新毎に1インクリメント

(0～3のリングカウンタ)";
BA_ "DescriptionE" SG_ 884 METER_ALIVE_COUNTER_374 "Incremented by 1 every time a packet is refreshed.(0 to 3 ring counters)";
BA_ "ValueTableE" SG_ 661 METER_DWS_INIT_REQ_SW "1: Request DWS initialization";
BA_ "ValueTableE" SG_ 661 METER_DWS_INIT_REQ "1: Request DWS initialization";
BA_ "ValueTableE" SG_ 426 VSA_SHIFT_REQ_1AA "0: No shift control request from VSA?(EAT?original control)

1: ?Request shift hold

2: Request upshift

3: Request downshift";
BA_ "DescriptionE" SG_ 426 VSA_SHIFT_REQ_1AA "VSA shift control request

ID:?Valid only when the data of 1AAh 2.1-2.0 VSA_TRQ_CONTROL_MODE is '2.'";
BA_ "DescriptionJ" SG_ 426 VSA_SHIFT_REQ_1AA "VSAシフト制御要求

ID: 1AAh 2.1-2.0 VSA_TRQ_CONTROL_MODE のデータが '2' の時のみ有効とする。";
BA_ "ValueTableE" SG_ 426 VSA_TRQ_DOWN_REQ_FUEL_CUT_1AA "0: No fuel/ignition control (THL?control only)

1: Ignition retard

2: ?All cylinders F/C + Ignition?retard";
BA_ "DescriptionE" SG_ 426 VSA_TRQ_DOWN_REQ_FUEL_CUT_1AA "Fuel control request signal

ID:?Valid only when the data of 1AAh 2.1-2.0 VSA_TRQ_CONTROL_MODE is '2.'";
BA_ "DescriptionJ" SG_ 426 VSA_TRQ_DOWN_REQ_FUEL_CUT_1AA "燃料制御要求信号

ID: 1AAh 2.1-2.0 VSA_TRQ_CONTROL_MODE のデータが '2' の時のみ有効とする。";
BA_ "DescriptionE" SG_ 426 VSA_ALIVE_COUNTER_1AA "Incremented by 1 every time a packet is refreshed.

(0 to 3 ring counters)";
BA_ "DescriptionJ" SG_ 426 VSA_ALIVE_COUNTER_1AA "1パケット更新毎に1インクリメント

(0～3のリングカウンタ)";
BA_ "ValueTableE" SG_ 426 VSA_REQ_MSR_PLUS_TRQ_1AA "1: ?Positive torque requested";
BA_ "DescriptionE" SG_ 426 VSA_REQ_MSR_PLUS_TRQ_1AA "MSR?positive torque request flag";
BA_ "DescriptionJ" SG_ 426 VSA_REQ_MSR_PLUS_TRQ_1AA "ＭＳＲプラストルク要求フラグ";
BA_ "ValueTableE" SG_ 426 VSA_TRQ_CONTROL_MODE_1AA "0: VSA/TCS control inactive (normal)

1: Request MSR?control

2: Request acceleration control (This value is set when engine control is required)

3: Inhibit VSA/TCS (VSA?failure)";
BA_ "DescriptionE" SG_ 426 VSA_TRQ_CONTROL_MODE_1AA "Control mode

If the data has remained '3'?for 70 msec, the VSA is judged faulty and no request will be accepted from the VSA?until a reset is performed via IG?operation.";
BA_ "DescriptionJ" SG_ 426 VSA_TRQ_CONTROL_MODE_1AA "制御モード

データが '3' が70msec継続した場合、VSA故障と判断し以後IG操作によるﾘｾｯﾄまでVSAからの要求を受け付けない事とする。";
BA_ "DescriptionE" SG_ 426 VSA_REQ_TRQ_1AA "Indicates the crankshaft torque.

-32768 to 32767 Nm

Indicates the crankshaft torque. ";
BA_ "DescriptionJ" SG_ 426 VSA_REQ_TRQ_1AA "クランクシャフトトルクを示す

-32768～32767Nm

クランクシャフトトルクを示す";
BA_ "GenSigStartValue" SG_ 506 ACC_TARGET_CALIPER_PRESSURE_FR 1020;
BA_ "GenSigStartValue" SG_ 506 ACC_TARGET_CALIPER_PRESSURE_FL 1020;
BA_ "GenSigStartValue" SG_ 316 ENG_SHFT_IN_REVERSE_13C 1;
BA_ "DescriptionJ" SG_ 316 ENG_SHFT_IN_REVERSE_13C "*";
BA_ "ValueTableE" SG_ 316 ENG_SHFT_IN_REVERSE_13C "*";
BA_ "ValueTableE" SG_ 316 ENG_CLUTCH_SW_CC_13C "1: Clutch pedal is not depressed(SW ON)

0: Clutch pedal is depressed(SW OFF)";
BA_ "DescriptionE" SG_ 316 ENG_CLUTCH_SW_CC_13C "Clutch sw signal for Cruise control";
BA_ "DescriptionJ" SG_ 316 ENG_CLUTCH_SW_CC_13C "クルーズコントロール用クラッチスイッチ信号";
BA_ "GenSigStartValue" SG_ 316 ENG_CLUTCH_SW_CC_13C 1;
BA_ "ValueTableE" SG_ 316 ENG_VSA_ACK1_13C "0: No fuel/ignition control (THL?control only)

1: Ignition retard

2: ?All cylinders in the F/C mode";
BA_ "DescriptionE" SG_ 316 ENG_VSA_ACK1_13C "Response to VSA fuel control request";
BA_ "DescriptionJ" SG_ 316 ENG_VSA_ACK1_13C "VSA燃料制御要求への応答     ";
BA_ "ValueTableE" SG_ 316 ENG_VSA_PERMIT_PLUS_TRQ_13C "1: ?Positive torque permitted";
BA_ "DescriptionE" SG_ 316 ENG_VSA_PERMIT_PLUS_TRQ_13C "MSR?positive torque permission flag";
BA_ "DescriptionJ" SG_ 316 ENG_VSA_PERMIT_PLUS_TRQ_13C "ＭＳＲプラストルク許可フラグ";
BA_ "DescriptionE" SG_ 316 ENG_ALIVE_COUNTER_13C "Incremented by 1 every time a packet is refreshed.

(0 to 3 ring counters)";
BA_ "DescriptionJ" SG_ 316 ENG_ALIVE_COUNTER_13C "1パケット更新毎に1インクリメント

(0～3のリングカウンタ)";
BA_ "ValueTableE" SG_ 316 ENG_RECEIVE_ERROR_1AA "1: Reception error detected";
BA_ "DescriptionE" SG_ 316 ENG_RECEIVE_ERROR_1AA "Flag indicating whether or not a reception error is present

ID:?'1'?if at least one of the 1AAh alive counter refresh error, checksum error or timeout has continued for 60 msec.";
BA_ "DescriptionJ" SG_ 316 ENG_RECEIVE_ERROR_1AA "受信エラーの有無を示すフラグ

ID: 1AAhのアライブカウンタ更新異常、チェックサム異常、タイムアウトの少なくとも一つが60msec間継続した場合'1'とする";
BA_ "ValueTableE" SG_ 316 ENG_VSA_INHIBIT_VSA_CONTROL_13C "1: VSA F/C?control temporarily stopped";
BA_ "DescriptionE" SG_ 316 ENG_VSA_INHIBIT_VSA_CONTROL_13C "VSA control permission/inhibition information";
BA_ "DescriptionJ" SG_ 316 ENG_VSA_INHIBIT_VSA_CONTROL_13C "VSA制御許可／禁止情報 ";
BA_ "ValueTableE" SG_ 316 ENG_VSA_REFUSED_VSA_CONTROL_13C "1: ?Failure that disables VSA control is present";
BA_ "DescriptionE" SG_ 316 ENG_VSA_REFUSED_VSA_CONTROL_13C "VSA control permission/inhibition information";
BA_ "DescriptionJ" SG_ 316 ENG_VSA_REFUSED_VSA_CONTROL_13C "VSA制御許可／禁止情報 ";
BA_ "DescriptionE" SG_ 316 ENG_SMART_ACCELE_PEDAL_POS_13C "Acceleration pedal position (%)

( at the time of a Smart Pedal System Application )";
BA_ "DescriptionJ" SG_ 316 ENG_SMART_ACCELE_PEDAL_POS_13C "アクセルペダル位置

（スマートペダルシステム適用時）";
BA_ "DescriptionE" SG_ 316 ENG_DRIVER_REQ_TRQ_13C "Indicates the driver-requested crankshaft driving torque.

Cruise-requested crankshaft driving torque during cruise control.";
BA_ "DescriptionJ" SG_ 316 ENG_DRIVER_REQ_TRQ_13C "ドライバー要求クランクシャフト駆動トルクを示す

クルーズコントロール中はクルーズ要求クランクシャフト駆動トルクとする";
BA_ "DescriptionE" SG_ 316 ENG_ENG_TRQ_13C "Indicates the crankshaft torque.

-32768 to 32767 Nm";
BA_ "DescriptionJ" SG_ 316 ENG_ENG_TRQ_13C "クランクシャフトトルクを示す

-32768～32767Nm";
BA_ "DescriptionE" SG_ 985 VSA_ALIVE_COUNTER_3D9 "Incremented by 1 every time a packet is refreshed.

(0 to 3 ring counters)";
BA_ "DescriptionJ" SG_ 985 VSA_ALIVE_COUNTER_3D9 "1パケット更新毎に1インクリメント

(0～3のリングカウンタ)";
BA_ "DescriptionJ" SG_ 985 VSA_ABS_DISABLE_EDR "ABS故障フラグ。EDR用。";
BA_ "CommentTxJ" SG_ 985 VSA_STABILITY_CTRL1_DISABLE_EDR "ABSユニットの様に、STABILITY CONTROL1を1つも装備しない場合は、'0'固定とする。

また、VSAオフ状態は、「禁止」には含めない。";
BA_ "DescriptionJ" SG_ 985 VSA_STABILITY_CTRL1_DISABLE_EDR "EDR用

STABILITY CONTROL1制御禁止フラグ";
BA_ "ValueTableE" SG_ 985 VSA_STABILITY_CTRL1_DISABLE_EDR "0: STABILITY CONTROL1 ENABLE

1: STABILITY CONTROL1 DISABLE";
BA_ "CommentTxJ" SG_ 985 VSA_STABILITY_CTRL2_DISABLE_EDR "ABSユニットやTSA機能を持たないVSAユニットの様に、STABILITY CONTROL2を1つも装備しない場合は、'0'固定とする。

また、VSAオフ状態は、「禁止」には含めない。";
BA_ "DescriptionJ" SG_ 985 VSA_STABILITY_CTRL2_DISABLE_EDR "EDR用

STABILITY CONTROL2制御禁止フラグ";
BA_ "ValueTableE" SG_ 985 VSA_STABILITY_CTRL2_DISABLE_EDR "0: STABILITY CONTROL2 ENABLE

1: STABILITY CONTROL2 DISABLE";
BA_ "DescriptionJ" SG_ 985 VSA_VSA_EQUIPPED_EDR "VSA装備フラグ。EDR用。";
BA_ "DescriptionJ" SG_ 985 VSA_ABS_ACT_EDR "ABS作動フラグ。EDR用。";
BA_ "DescriptionJ" SG_ 985 VSA_STABILITY_CTRL_ACT_EDR "STABILITY CONTROL 作動フラグ。EDR用。";
BA_ "DescriptionJ" SG_ 985 VSA_VSA_OFF_STATUS_EDR "VSA OFF SW 操作による VSA OFF 状態。EDR用。";
BA_ "DescriptionE" SG_ 2564550641 HDS_HDC_CAN "Data frame for failure diagnosis/reprogramming

Refer to 'Function Request for ECU Not Implementing HDC_CAN Protocol.'";
BA_ "DescriptionJ" SG_ 2564550641 HDS_HDC_CAN "故障診断･リプログラミング用のデータ･フレーム

『HDC_CAN プロトコル非実装 ECU に対する機能要求』を参照";
BA_ "DescriptionE" SG_ 808 ENG_ALIVE_COUNTER_328 "Incremented by 1 every time a packet is refreshed.

(0 to 3 ring counters)";
BA_ "DescriptionJ" SG_ 808 ENG_ALIVE_COUNTER_328 "1パケット更新毎に1インクリメント

(0～3のリングカウンタ)";
BA_ "DescriptionE" SG_ 808 ENG_STRNNEND "Engine complete combustion judgment flag";
BA_ "DescriptionJ" SG_ 808 ENG_STRNNEND "ENG完爆判定フラグ";
BA_ "ValueTableE" SG_ 808 ENG_STRNNEND "1: Complete combustion";
BA_ "DescriptionE" SG_ 804 ENG_ALIVE_COUNTER_324 "Incremented by 1 every time a packet is refreshed.

(0 to 3 ring counters)";
BA_ "DescriptionJ" SG_ 804 ENG_ALIVE_COUNTER_324 "1パケット更新毎に1インクリメント

(0～3のリングカウンタ)";
BA_ "ValueTableE" SG_ 804 ENG_SW_STATUS_SCS "1: SCS SW ON";
BA_ "DescriptionJ" SG_ 472 SS30_SYSTEM_ACT "*";
BA_ "DescriptionE" SG_ 472 SS30_SYSTEM_ACT "0";
BA_ "DescriptionE" SG_ 472 SS30_ALIVE_COUNTER_1D8 "Incremented by 1 every time a packet is refreshed.

(0 to 3 ring counters)";
BA_ "DescriptionJ" SG_ 472 SS30_ALIVE_COUNTER_1D8 "1パケット更新毎に1インクリメント

(0～3のリングカウンタ)";
BA_ "DescriptionJ" SG_ 472 SS30_TARGET_DECELERATION "SS30要求減速指示値";
BA_ "GenSigStartValue" SG_ 472 SS30_TARGET_DECELERATION -1024;
BA_ "DescriptionJ" SG_ 472 SS30_REQ_PREBRAKE "SS30予圧要求";
BA_ "DescriptionJ" SG_ 472 SS30_REQ_BRAKE "SS30減速要求";
BA_ "DescriptionJ" SG_ 472 SS30_REQ_BRAKEHOLD "SS30ブレーキ保持要求";
BA_ "DescriptionE" SG_ 472 SS30_STATUS_FAIL "0";
BA_ "DescriptionJ" SG_ 472 SS30_STATUS_FAIL "SS30故障フラグ";
BA_ "DescriptionE" SG_ 356 METER_ALIVE_COUNTER_164 "Incremented by 1 every time a packet is refreshed.

(0 to 3 ring counters)";
BA_ "DescriptionJ" SG_ 356 METER_ALIVE_COUNTER_164 "1パケット更新毎に1インクリメント

(0～3のリングカウンタ)";
BA_ "ValueTableE" SG_ 356 METER_SW_STATUS_PARK_BRAKE "1: Parking brake SW ON";
BA_ "ValueTableE" SG_ 356 METER_SW_STATUS_BRAKE_FLUID "1: Brake fluid level SW ON";
BA_ "ValueTableE" SG_ 356 METER_SW_STATUS_VSA_OFF "1: VSA-off SW ON";
BA_ "ValueTableE" SG_ 401 CVT_CAS_ON "1: ?CAS_ON?request to VSA";
BA_ "DescriptionE" SG_ 401 CVT_ALIVE_COUNTER_191 "Incremented by 1 every time a packet is refreshed.

(0 to 3 ring counters)";
BA_ "DescriptionJ" SG_ 401 CVT_ALIVE_COUNTER_191 "1パケット更新毎に1インクリメント

(0～3のリングカウンタ)";
BA_ "DescriptionE" SG_ 401 CVT_RATIO_TARGET "Target ratio information";
BA_ "DescriptionJ" SG_ 401 CVT_RATIO_TARGET "目標レシオ情報";
BA_ "GenSigStartValue" SG_ 401 CVT_RATIO_TARGET 64;
BA_ "DescriptionE" SG_ 401 CVT_RATIO_INFO_191 "Ratio information";
BA_ "DescriptionJ" SG_ 401 CVT_RATIO_INFO_191 "レシオ情報";
BA_ "GenSigStartValue" SG_ 401 CVT_RATIO_INFO_191 64;
BA_ "ValueTableE" SG_ 401 CVT_REFUSE_VSA_CONTROL "1: ?CVT?failure that disables VSA control is present";
BA_ "DescriptionE" SG_ 401 CVT_GEAR_POSITION_IND_CVT "Shift position indication for S-Matic

For S-Matic LED indication

8-E: OFF";
BA_ "DescriptionJ" SG_ 401 CVT_GEAR_POSITION_IND_CVT "S-Matic用 シフト段表示

S-Matic LED表示用

9-E: オフ";
BA_ "ValueTableE" SG_ 401 CVT_GEAR_POSITION_IND_CVT "0: OFF

1: 1st

2: 2nd

3: 3rd

4: 4th

5: 5th

6: 6th

7: 7th

8: 8th

F: ?L range control active";
BA_ "DescriptionE" SG_ 401 CVT_SHFT_IN_PARKING "Select lever position";
BA_ "DescriptionJ" SG_ 401 CVT_SHFT_IN_PARKING "セレクトレバー位置";
BA_ "ValueTableE" SG_ 401 CVT_SHFT_IN_PARKING "1: Parking";
BA_ "DescriptionE" SG_ 401 CVT_SHFT_IN_REVERSE "Select lever position";
BA_ "DescriptionJ" SG_ 401 CVT_SHFT_IN_REVERSE "セレクトレバー位置";
BA_ "ValueTableE" SG_ 401 CVT_SHFT_IN_REVERSE "1: Reverse";
BA_ "DescriptionE" SG_ 401 CVT_SHFT_IN_NEUTRAL "Select lever position";
BA_ "DescriptionJ" SG_ 401 CVT_SHFT_IN_NEUTRAL "セレクトレバー位置";
BA_ "ValueTableE" SG_ 401 CVT_SHFT_IN_NEUTRAL "1: Neutral";
BA_ "DescriptionE" SG_ 401 CVT_SHFT_IN_D "Select lever position";
BA_ "DescriptionJ" SG_ 401 CVT_SHFT_IN_D "セレクトレバー位置";
BA_ "ValueTableE" SG_ 401 CVT_SHFT_IN_D "1: 'D'";
BA_ "DescriptionE" SG_ 401 CVT_SHFT_IN_S "Select lever position

Meter 'S' lighting information

* S lighting information under the following two specifications

- 'S range' on the shift lever

 - 'Sports mode (SPO-IND)' effected by the S SW?";
BA_ "DescriptionJ" SG_ 401 CVT_SHFT_IN_S "セレクトレバー位置

ﾒｰﾀ”S”点灯情報

※下記2仕様におけるS点灯情報

・ｼﾌﾄﾚﾊﾞｰ”Sﾚﾝｼﾞ”

 ・S SWによる”ｽﾎﾟｰﾂﾓｰﾄﾞ（SPO-IND）” ";
BA_ "ValueTableE" SG_ 401 CVT_SHFT_IN_S "1: 'S'";
BA_ "DescriptionE" SG_ 401 CVT_SHFT_IN_L "Select lever position";
BA_ "DescriptionJ" SG_ 401 CVT_SHFT_IN_L "セレクトレバー位置";
BA_ "ValueTableE" SG_ 401 CVT_SHFT_IN_L "1: 'L'";
BA_ "DescriptionE" SG_ 380 ENG_ALIVE_COUNTER_17C "Incremented by 1 every time a packet is refreshed.

(0 to 3 ring counters)";
BA_ "DescriptionJ" SG_ 380 ENG_ALIVE_COUNTER_17C "1パケット更新毎に1インクリメント

(0～3のリングカウンタ)";
BA_ "DescriptionJ" SG_ 380 ENG_IS_PRE_PROGRESS "アイドルストップをする前から復帰予告の間に立てるフラグ（METER PCUガイダンス表示取消し用）";
BA_ "DescriptionJ" SG_ 380 ENG_IS_PRE_RESTART "アイドルストップから復帰する際の予告フラグ";
BA_ "ValueTableE" SG_ 380 ENG_IS_PROGRESS "1: ?Idle stop control started or in progress";
BA_ "DescriptionE" SG_ 380 ENG_SW_STATUS_BRAKE_NO "The brake switch NO indicates the brake mode.

(SW ON)";
BA_ "DescriptionJ" SG_ 380 ENG_SW_STATUS_BRAKE_NO "ブレーキスイッチNOがブレーキ中状態を示す  

(スイッチ on)";
BA_ "ValueTableE" SG_ 380 ENG_CRUISE_STATUS_CRUISE_LMP "1: Cruise control lamp ON";
BA_ "DescriptionE" SG_ 380 ENG_ENG_SPEED "Engine speed

0 to 15000 rpm";
BA_ "DescriptionJ" SG_ 380 ENG_ENG_SPEED "エンジン回転数

0～15000rpm";
BA_ "DescriptionE" SG_ 342 STR_ALIVE_COUNTER_156 "Incremented by 1 every time a packet is refreshed.

(0 to 3 ring counters)";
BA_ "DescriptionJ" SG_ 342 STR_ALIVE_COUNTER_156 "1パケット更新毎に1インクリメント

(0～3のリングカウンタ)";
BA_ "DescriptionE" SG_ 342 STR_OK "OK flag: Indicates that the sensor is normal.

- 1 is output when normal.";
BA_ "DescriptionJ" SG_ 342 STR_OK "OKフラグ: センサが正常であることを表す

・正常時に1を出力";
BA_ "GenSigStartValue" SG_ 342 STR_OK 1;
BA_ "DescriptionE" SG_ 342 STR_CAL "Calibration flag:?Indicates whether or not zero is set.

- 1 is output when set.

Becomes '1'?if zero is set after installation on the vehicle.";
BA_ "DescriptionJ" SG_ 342 STR_CAL "キャリブレーションフラグ: ０点設定の有無を表す

・設定時に1を出力

車輌搭搭載後に0点設定を行うと”1”となる";
BA_ "GenSigStartValue" SG_ 342 STR_CAL 1;
BA_ "DescriptionE" SG_ 342 STR_ANGLE "Steering angle signal";
BA_ "DescriptionJ" SG_ 342 STR_ANGLE "操舵角信号";
BA_ "ValueTableE" SG_ 342 STR_ANGLE "E278: -756[deg]

0000: 0[deg]

1D88: +756[deg]

7FFF: Invalid";
BA_ "GenSigStartValue" SG_ 304 ENG_SHFT_IN_REVERSE 1;
BA_ "DescriptionJ" SG_ 304 ENG_SHFT_IN_REVERSE "*";
BA_ "DescriptionE" SG_ 304 ENG_SHFT_IN_REVERSE "*";
BA_ "ValueTableE" SG_ 304 ENG_SHFT_IN_REVERSE "*";
BA_ "DescriptionE" SG_ 304 ENG_ALIVE_COUNTER_130 "Incremented by 1 every time a packet is refreshed.

(0 to 3 ring counters)";
BA_ "DescriptionJ" SG_ 304 ENG_ALIVE_COUNTER_130 "1パケット更新毎に1インクリメント

(0～3のリングカウンタ)";
BA_ "CommentTxJ" SG_ 304 ENG_NEUTRAL_SENSOR_FAIL "MT車用";
BA_ "ValueTableE" SG_ 304 ENG_NEUTRAL_SENSOR_FAIL "1: NEUTRAL SENSOR FAIL";
BA_ "DescriptionE" SG_ 304 ENG_RECEIVE_ERROR_1AC "Flag indicating whether or not a reception error is present

ID:?'1'?if at least one of the 1AAh alive counter refresh error, checksum error or timeout has continued for 60 msec.";
BA_ "DescriptionJ" SG_ 304 ENG_RECEIVE_ERROR_1AC "受信エラーの有無を示すフラグ

ID: 1AAhのアライブカウンタ更新異常、チェックサム異常、タイムアウトの少なくとも一つが60msec間継続した場合'1'とする";
BA_ "ValueTableE" SG_ 304 ENG_RECEIVE_ERROR_1AC "1: Reception error detected";
BA_ "CommentTxJ" SG_ 304 ENG_SHFT_IN_NEUTRAL "MT車用";
BA_ "ValueTableE" SG_ 304 ENG_SHFT_IN_NEUTRAL "1: SHIFT LEVER IS IN NEUTRAL";
BA_ "DescriptionE" SG_ 304 ENG_CLUTCH_SW_CC "Clutch sw signal for Cruise control";
BA_ "DescriptionJ" SG_ 304 ENG_CLUTCH_SW_CC "クルーズコントロール用クラッチスイッチ信号";
BA_ "ValueTableE" SG_ 304 ENG_CLUTCH_SW_CC "1: Clutch pedal is not depressed(SW ON)

0: Clutch pedal is depressed(SW OFF)";
BA_ "GenSigStartValue" SG_ 304 ENG_CLUTCH_SW_CC 1;
BA_ "DescriptionE" SG_ 304 ENG_VSA_ACK1 "Response to VSA fuel control request";
BA_ "DescriptionJ" SG_ 304 ENG_VSA_ACK1 "VSA燃料制御要求への応答     ";
BA_ "ValueTableE" SG_ 304 ENG_VSA_ACK1 "0: No fuel/ignition control (THL?control only)

1: Ignition retard

2: ?All cylinders in the F/C mode";
BA_ "DescriptionE" SG_ 304 ENG_VSA_PERMIT_PLUS_TRQ "MSR?positive torque permission flag";
BA_ "DescriptionJ" SG_ 304 ENG_VSA_PERMIT_PLUS_TRQ "ＭＳＲプラストルク許可フラグ";
BA_ "ValueTableE" SG_ 304 ENG_VSA_PERMIT_PLUS_TRQ "1: ?Positive torque permitted";
BA_ "DescriptionE" SG_ 304 ENG_VSA_INHIBIT_VSA_CONTROL "VSA control permission/inhibition information";
BA_ "DescriptionJ" SG_ 304 ENG_VSA_INHIBIT_VSA_CONTROL "VSA制御許可／禁止情報 ";
BA_ "ValueTableE" SG_ 304 ENG_VSA_INHIBIT_VSA_CONTROL "1: VSA F/C?control temporarily stopped";
BA_ "DescriptionE" SG_ 304 ENG_VSA_REFUSED_VSA_CONTROL "VSA control permission/inhibition information";
BA_ "DescriptionJ" SG_ 304 ENG_VSA_REFUSED_VSA_CONTROL "VSA制御許可／禁止情報 ";
BA_ "ValueTableE" SG_ 304 ENG_VSA_REFUSED_VSA_CONTROL "1: ?Failure that disables VSA control is present";
BA_ "DescriptionE" SG_ 304 ENG_SMART_ACCELE_PEDAL_POSITION "Acceleration pedal position (%)

( at the time of a Smart Pedal System Application )";
BA_ "DescriptionJ" SG_ 304 ENG_SMART_ACCELE_PEDAL_POSITION "アクセルペダル位置

（スマートペダルシステム適用時）";
BA_ "DescriptionE" SG_ 304 ENG_DRIVER_REQ_TRQ_130 "Indicates the driver-requested crankshaft driving torque.

Cruise-requested crankshaft driving torque during cruise control.";
BA_ "DescriptionJ" SG_ 304 ENG_DRIVER_REQ_TRQ_130 "ドライバー要求クランクシャフト駆動トルクを示す

クルーズコントロール中はクルーズ要求クランクシャフト駆動トルクとする";
BA_ "GenSigStartValue" SG_ 304 ENG_DRIVER_REQ_TRQ_130 32767;
BA_ "DescriptionE" SG_ 304 ENG_ENG_TRQ_130 "Indicates the crankshaft torque.

-32768 to 32767 Nm";
BA_ "DescriptionJ" SG_ 304 ENG_ENG_TRQ_130 "クランクシャフトトルクを示す

-32768～32767Nm";
BA_ "GenSigStartValue" SG_ 304 ENG_ENG_TRQ_130 32767;
BA_ "DescriptionJ" SG_ 1934 VSA_ALIVE_COUNTER_78E "1パケット更新毎に1インクリメント

(0～3のリングカウンタ)";
BA_ "DescriptionJ" SG_ 1934 VSA_COMMAND_CODE "コマンドコード

【要求コマンド】";
BA_ "ValueTableE" SG_ 1934 VSA_COMMAND_CODE "3: Calibration

5: Reset of the Calibration";
BA_ "DescriptionE" SG_ 1030 VSA_ALIVE_COUNTER_406 "Incremented by 1 every time a packet is refreshed.

(0 to 3 ring counters)";
BA_ "DescriptionJ" SG_ 1030 VSA_ALIVE_COUNTER_406 "1パケット更新毎に1インクリメント

(0～3のリングカウンタ)";
BA_ "DescriptionJ" SG_ 1030 VSA_SPECIFY_CODE_SYS "DTC体系

VSA送信信号はHMコードなので，1h固定値。";
BA_ "GenSigStartValue" SG_ 1030 VSA_SPECIFY_CODE_SYS 1;
BA_ "DescriptionJ" SG_ 1030 VSA_DTC_STORAGE "DTC格納状態";
BA_ "DescriptionJ" SG_ 1030 VSA_DTC_LOW "DTCコード下位側

VSAは未使用のため0固定";
BA_ "DescriptionJ" SG_ 1030 VSA_DTC_HIGH "DTCコード上位側

今回確定のDTCのみ

複数の場合、300msecサイクルとする";
BA_ "DescriptionE" SG_ 597 VSA_ABS_CHECKSUM_255 "CAN checksum for ESL?(255h)";
BA_ "DescriptionJ" SG_ 597 VSA_ABS_CHECKSUM_255 "ESL用CANチェックサム（255h）";
BA_ "DescriptionE" SG_ 597 VSA_ABS_ALIVE_COUNTER_255 "CAN alive counter for ESL";
BA_ "DescriptionJ" SG_ 597 VSA_ABS_ALIVE_COUNTER_255 "ESL用CANアライブカウンタ";
BA_ "DescriptionE" SG_ 597 VSA_ABS_SPEED_FIXED_NUMBER2 "Fixed checksum value (ESL)

A fixed value of 0x55 is sent (also in the initial state).";
BA_ "DescriptionJ" SG_ 597 VSA_ABS_SPEED_FIXED_NUMBER2 "チェックサム用固定値（ESL用）

固定値0x55を送信（ｲﾆｼｬﾙ時含む）";
BA_ "GenSigStartValue" SG_ 597 VSA_ABS_SPEED_FIXED_NUMBER2 85;
BA_ "DescriptionE" SG_ 597 VSA_ABS_SPEED_FIXED_NUMBER1 "Fixed checksum value (ESL)

A fixed value of 0x55 is sent (also in the initial state).";
BA_ "DescriptionJ" SG_ 597 VSA_ABS_SPEED_FIXED_NUMBER1 "チェックサム用固定値（ESL用）

固定値0x55を送信（ｲﾆｼｬﾙ時含む）";
BA_ "GenSigStartValue" SG_ 597 VSA_ABS_SPEED_FIXED_NUMBER1 85;
BA_ "DescriptionE" SG_ 597 VSA_ABS_RR_WHEEL_SPEED_255 "Right rear wheel speed  If failure occurs value is converted directly to speed. 

FFh shall be sent if the measured value has overflowed due to an open failure.

If Noise causes high vehicle speed shall be sent but, upper limit is clipped at 250 km/h.";
BA_ "DescriptionJ" SG_ 597 VSA_ABS_RR_WHEEL_SPEED_255 "右後輪車速

ｾﾝｻｰ故障時も計測値をそのまま車速変換の事。

断線故障にて計測ｵｰﾊﾞｰﾌﾛｰ時はFFh

ﾉｲｽﾞによる高車速計測時はその車速を送信の事（但し上限250km/h）";
BA_ "GenSigStartValue" SG_ 597 VSA_ABS_RR_WHEEL_SPEED_255 250;
BA_ "DescriptionE" SG_ 597 VSA_ABS_RL_WHEEL_SPEED_255 "Left rear wheel speed  If failure occurs value is converted directly to speed. 

FFh shall be sent if the measured value has overflowed due to an open failure.

If Noise causes high vehicle speed shall be sent but, upper limit is clipped at 250 km/h.";
BA_ "DescriptionJ" SG_ 597 VSA_ABS_RL_WHEEL_SPEED_255 "左後輪車速

ｾﾝｻｰ故障時も計測値をそのまま車速変換の事。

断線故障にて計測ｵｰﾊﾞｰﾌﾛｰ時はFFh

ﾉｲｽﾞによる高車速計測時はその車速を送信の事（但し上限250km/h）";
BA_ "GenSigStartValue" SG_ 597 VSA_ABS_RL_WHEEL_SPEED_255 250;
BA_ "DescriptionE" SG_ 597 VSA_ABS_FR_WHEEL_SPEED_255 "Right front wheel speed If failure occurs value is converted directly to speed. 

FFh shall be sent if the measured value has overflowed due to an open failure.

If Noise causes high vehicle speed shall be sent but, upper limit is clipped at 250 km/h.";
BA_ "DescriptionJ" SG_ 597 VSA_ABS_FR_WHEEL_SPEED_255 "右前輪車速

ｾﾝｻｰ故障時も計測値をそのまま車速変換の事。

断線故障にて計測ｵｰﾊﾞｰﾌﾛｰ時はFFh

ﾉｲｽﾞによる高車速計測時はその車速を送信の事（但し上限250km/h）";
BA_ "GenSigStartValue" SG_ 597 VSA_ABS_FR_WHEEL_SPEED_255 250;
BA_ "DescriptionE" SG_ 597 VSA_ABS_FL_WHEEL_SPEED_255 "Left front wheel speed If failure occurs value is converted directly to speed. 

FFh shall be sent if the measured value has overflowed due to an open failure.

If Noise causes high vehicle speed shall be sent but, upper limit is clipped at 250 km/h.

";
BA_ "DescriptionJ" SG_ 597 VSA_ABS_FL_WHEEL_SPEED_255 "左前輪車速

ｾﾝｻｰ故障時も計測値をそのまま車速変換の事。

断線故障にて計測ｵｰﾊﾞｰﾌﾛｰ時はFFh

ﾉｲｽﾞによる高車速計測時はその車速を送信の事（但し上限250km/h）";
BA_ "GenSigStartValue" SG_ 597 VSA_ABS_FL_WHEEL_SPEED_255 250;
BA_ "DescriptionE" SG_ 490 VSA_ALIVE_COUNTER_1EA "Incremented by 1 every time a packet is refreshed.

(0 to 3 ring counters)";
BA_ "DescriptionJ" SG_ 490 VSA_ALIVE_COUNTER_1EA "1パケット更新毎に1インクリメント

(0～3のリングカウンタ)";
BA_ "DescriptionE" SG_ 490 VSA_MAEPS_REVERSE_F "VSA status signal 1";
BA_ "DescriptionJ" SG_ 490 VSA_MAEPS_REVERSE_F "VSA状態信号1";
BA_ "ValueTableE" SG_ 490 VSA_MAEPS_REVERSE_F "1: Reverse";
BA_ "DescriptionE" SG_ 490 VSA_SYSTEM_F "VSA status signal 3";
BA_ "DescriptionJ" SG_ 490 VSA_SYSTEM_F "VSA状態信号3";
BA_ "ValueTableE" SG_ 490 VSA_SYSTEM_F "1: VSA system failure";
BA_ "DescriptionE" SG_ 490 VSA_MAEPS_MYU_VALUE "m ratio signal";
BA_ "DescriptionJ" SG_ 490 VSA_MAEPS_MYU_VALUE "μﾚｼｵ信号";
BA_ "DescriptionE" SG_ 490 VSA_MAEPS_GX_VALUE "Estimate vehicle front/rear G signal";
BA_ "DescriptionJ" SG_ 490 VSA_MAEPS_GX_VALUE "推定車体前後G信号";
BA_ "DescriptionE" SG_ 490 VSA_MAEPS_US_VALUE "Yaw rate deviation signal";
BA_ "DescriptionJ" SG_ 490 VSA_MAEPS_US_VALUE "ﾖｰﾚｰﾄ偏差信号";
BA_ "DescriptionJ" SG_ 487 VSA_ALIVE_COUNTER_1E7 "1パケット更新毎に1インクリメント

(0～3のリングカウンタ)";
BA_ "DescriptionJ" SG_ 487 VSA_HSA_STATUS_ACT_1E7 "HSAが作動している状態を示す";
BA_ "GenSigStartValue" SG_ 487 VSA_CALIPPER_PRESSURE_FR 102;
BA_ "DescriptionJ" SG_ 487 VSA_CALIPPER_PRESSURE_FR "FR輪キャリパー液圧

(ｾﾝｻA/D生値)

センサ出力範囲

0～19623.24kPa

0066h=0kPa(0.5V)

0399h=19623.24kPa(4.5V)

Diag出力があるので注意";
BA_ "DescriptionJ" SG_ 487 VSA_INHBIT_CALIPPER_PRESSURE_FR "キャリパ液圧センサFR一時禁止フラグ";
BA_ "DescriptionJ" SG_ 487 VSA_FAIL_CALIPPER_PRESSURE_FR "キャリパ液圧センサFR異常フラグ";
BA_ "DescriptionJ" SG_ 487 VSA_INHBIT_CALIPPER_PRESSURE_FL "キャリパ液圧センサFL一時禁止フラグ";
BA_ "DescriptionJ" SG_ 487 VSA_FAIL_CALIPPER_PRESSURE_FL "キャリパ液圧センサFL異常フラグ";
BA_ "GenSigStartValue" SG_ 487 VSA_CALIPPER_PRESSURE_FL 102;
BA_ "DescriptionJ" SG_ 487 VSA_CALIPPER_PRESSURE_FL "FL輪キャリパー液圧

(ｾﾝｻA/D生値)

センサ出力範囲

0～19623.24kPa

0066h=0kPa(0.5V)

0399h=19623.24kPa(4.5V)

Diag出力があるので注意";
BA_ "DescriptionE" SG_ 464 VSA_ABS_RR_WHEEL_SPEED "Right rear wheel speed

0~300 km/h

CAN outputs failed value even when sensor failure occurs. 

When Open 0000h shall be sent in overflow condition. If noise causes high vehicle speed the measured vehicle speed shall be sent but, upper limit is 300 km/h.";
BA_ "DescriptionJ" SG_ 464 VSA_ABS_RR_WHEEL_SPEED "右後輪車速

0～300km/h。

センサｰ故障時も計測値をそのまま車速変換の事。

(断線故障にて計測ｵｰﾊﾞｰﾌﾛｰ時は0000h、ﾉｲｽﾞによる高車速計測時はその車速を送信の事。但し上限300km/h)";
BA_ "DescriptionE" SG_ 464 VSA_ABS_RL_WHEEL_SPEED "Left rear wheel speed

0~300 km/h

CAN outputs failed value even when sensor failure occurs. 

When Open 0000h shall be sent in overflow condition. If noise causes high vehicle speed the measured vehicle speed shall be sent but, upper limit is 300 km/h.";
BA_ "DescriptionJ" SG_ 464 VSA_ABS_RL_WHEEL_SPEED "左後輪車速

0～300km/h。

センサｰ故障時も計測値をそのまま車速変換の事。

(断線故障にて計測ｵｰﾊﾞｰﾌﾛｰ時は0000h、ﾉｲｽﾞによる高車速計測時はその車速を送信の事。但し上限300km/h)";
BA_ "DescriptionE" SG_ 464 VSA_ABS_FR_WHEEL_SPEED "Right front wheel speed

0~300 km/h

CAN outputs failed value even when sensor failure occurs. 

When Open 0000h shall be sent in overflow condition. If noise causes high vehicle speed the measured vehicle speed shall be sent but, upper limit is 300 km/h";
BA_ "DescriptionJ" SG_ 464 VSA_ABS_FR_WHEEL_SPEED "右前輪車速

0～300km/h。

センサｰ故障時も計測値をそのまま車速変換の事。

(断線故障にて計測ｵｰﾊﾞｰﾌﾛｰ時は0000h、ﾉｲｽﾞによる高車速計測時はその車速を送信の事。但し上限300km/h)";
BA_ "DescriptionE" SG_ 464 VSA_ABS_FL_WHEEL_SPEED "Left front wheel speed 

0~300 km/h

CAN outputs failed value even when sensor failure occurs. 

When Open 0000h shall be sent in overflow condition. If noise causes high vehicle speed the measured vehicle speed shall be sent but, upper limit is 300 km/h";
BA_ "DescriptionJ" SG_ 464 VSA_ABS_FL_WHEEL_SPEED "左前輪車速

0～300km/h。

センサｰ故障時も計測値をそのまま

車速変換の事。

(断線故障にて計測ｵｰﾊﾞｰﾌﾛｰ

時は0000h、ﾉｲｽﾞによる

高車速計測時はその車速を

送信の事。但し上限300km/h)";
BA_ "DescriptionE" SG_ 432 VSA_ALIVE_COUNTER_1B0 "Incremented by 1 every time a packet is refreshed.

(0 to 3 ring counters)";
BA_ "DescriptionJ" SG_ 432 VSA_ALIVE_COUNTER_1B0 "1パケット更新毎に1インクリメント

(0～3のリングカウンタ)";
BA_ "DescriptionE" SG_ 432 VSA_REQ_CVT_TCS "CVT?control request

CVT?coordination control request signal";
BA_ "DescriptionJ" SG_ 432 VSA_REQ_CVT_TCS "CVT制御要求

CVT協調用制御要求信号";
BA_ "ValueTableE" SG_ 432 VSA_REQ_CVT_TCS "1: ?TCS operation permitted";
BA_ "DescriptionE" SG_ 432 VSA_REQ_CVT_PRS "CVT?control request

CVT?coordination control request signal";
BA_ "DescriptionJ" SG_ 432 VSA_REQ_CVT_PRS "CVT制御要求

CVT協調用制御要求信号";
BA_ "ValueTableE" SG_ 432 VSA_REQ_CVT_PRS "1: ?Pressurizing";
BA_ "DescriptionE" SG_ 432 VSA_CONTROL_MODE_CVT "CVT?coordination control mode

Dedicated CVT?coordination control mode";
BA_ "DescriptionJ" SG_ 432 VSA_CONTROL_MODE_CVT "CVT協調用制御モード

CVT協調用専用制御モード";
BA_ "ValueTableE" SG_ 432 VSA_CONTROL_MODE_CVT "0: VSA control ready

1: ?TCS active

2: Reserved

3: Reserved";
BA_ "ValueTableE" SG_ 432 VSA_ABS_STATUS_FR_ABS_EBD_ACT "1: ?FR?wheel ABS, EBD active";
BA_ "ValueTableE" SG_ 432 VSA_ABS_STATUS_FL_ABS_EBD_ACT "1: ?FL?wheel ABS, EBD active";
BA_ "ValueTableE" SG_ 432 VSA_ABS_STATUS_RR_ABS_EBD_ACT "1: ?RR?wheel ABS, EBD active";
BA_ "ValueTableE" SG_ 432 VSA_ABS_STATUS_RL_ABS_EBD_ACT "1: ?RL?wheel ABS, EBD active";
BA_ "ValueTableE" SG_ 432 VSA_FAIL_YAW_RATE_SENSOR "1: Yaw rate sensor error";
BA_ "ValueTableE" SG_ 432 VSA_ABS_FAIL_FR_VW_SENSOR "1: ?Wheel speed sensor; FR?wheel error";
BA_ "ValueTableE" SG_ 432 VSA_ABS_FAIL_FL_VW_SENSOR "1: ?Wheel speed sensor; FL?wheel error";
BA_ "ValueTableE" SG_ 432 VSA_ABS_FAIL_RR_VW_SENSOR "1: ?Wheel speed sensor; RR?wheel error";
BA_ "ValueTableE" SG_ 432 VSA_ABS_FAIL_RL_VW_SENSOR "1: ?Wheel speed sensor; RL?wheel error";
BA_ "DescriptionJ" SG_ 432 VSA_ABS_INHBIT_VW_SENSOR "車輪速センサ一時禁止フラグ";
BA_ "DescriptionE" SG_ 432 VSA_ACC_INHIBIT_CVRS_BRAKE "ACC brake control inhibition information

The default value is sent if there is no ACC.";
BA_ "DescriptionJ" SG_ 432 VSA_ACC_INHIBIT_CVRS_BRAKE "ACCブレーキ制御禁止情報

ACCなしの場合にはデフォルト値を送信する．";
BA_ "ValueTableE" SG_ 432 VSA_ACC_INHIBIT_CVRS_BRAKE "1: Temporarily inhibit CVRS brake";
BA_ "GenSigStartValue" SG_ 432 VSA_ACC_INHIBIT_CVRS_BRAKE 1;
BA_ "DescriptionJ" SG_ 432 VSA_INHBIT_STEERING_SENSOR "舵角センサ一時禁止フラグ";
BA_ "DescriptionE" SG_ 432 VSA_ACC_REFUSE_CVRS_BRAKE "ACC brake control inhibition information

The default value is sent if there is no ACC.";
BA_ "DescriptionJ" SG_ 432 VSA_ACC_REFUSE_CVRS_BRAKE "ACCブレーキ制御禁止情報

ACCなしの場合にはデフォルト値を送信する．";
BA_ "ValueTableE" SG_ 432 VSA_ACC_REFUSE_CVRS_BRAKE "1: ?Failure that disables CVRS brake occurred";
BA_ "GenSigStartValue" SG_ 432 VSA_ACC_REFUSE_CVRS_BRAKE 1;
BA_ "DescriptionE" SG_ 432 VSA_VW_PULSE_CAPTURED "Wheel speed pulse generation flag

The flag is set to '1' if a wheel speed pulse has generated at least once between the last transmission and this transmission.";
BA_ "DescriptionJ" SG_ 432 VSA_VW_PULSE_CAPTURED "車輪速ﾊﾟｽﾙ発生フラグ

前回の送信から今回の送信の間で，1回でも車輪速パルスが発生したら，フラグを1にｾｯﾄ";
BA_ "ValueTableE" SG_ 432 VSA_VW_PULSE_CAPTURED "1: Wheel speed pulse available";
BA_ "DescriptionE" SG_ 432 VSA_INHBIT_YAW_RATE_SENSOR "When a side collision is detected, '1' is sent with each message which is output 10 times continuously.";
BA_ "DescriptionJ" SG_ 432 VSA_INHBIT_YAW_RATE_SENSOR "ヨーレートセンサ一時禁止フラグ";
BA_ "DescriptionE" SG_ 428 VSA_IS_SHIFT_INHIBIT_REQUEST "When a side collision is detected, '1' is sent with each message which is output 10 times continuously.";
BA_ "DescriptionJ" SG_ 428 VSA_IS_SHIFT_INHIBIT_REQUEST "アイドルストップへの移行を禁止する場合“1”が送出される。";
BA_ "DescriptionE" SG_ 428 VSA_SHIFT_REQ_1AC "VSA shift control request

ID:?Valid only when the data of 1AAh 2.1-2.0 VSA_TRQ_CONTROL_MODE is '2.'";
BA_ "DescriptionJ" SG_ 428 VSA_SHIFT_REQ_1AC "VSAシフト制御要求

ID: 1AAh 2.1-2.0 VSA_TRQ_CONTROL_MODE のデータが '2' の時のみ有効とする。";
BA_ "ValueTableE" SG_ 428 VSA_SHIFT_REQ_1AC "0: No shift control request from VSA?(EAT?original control)

1: ?Request shift hold

2: Request upshift

3: Request downshift";
BA_ "DescriptionE" SG_ 428 VSA_ALIVE_COUNTER_1AC "Incremented by 1 every time a packet is refreshed.

(0 to 3 ring counters)";
BA_ "DescriptionJ" SG_ 428 VSA_ALIVE_COUNTER_1AC "1パケット更新毎に1インクリメント

(0～3のリングカウンタ)";
BA_ "DescriptionE" SG_ 428 VSA_REQ_TRQ_1AC "Indicates the crankshaft torque.

-32768 to 32767 Nm

Indicates the crankshaft torque. ";
BA_ "DescriptionJ" SG_ 428 VSA_REQ_TRQ_1AC "クランクシャフトトルクを示す

-32768～32767Nm

クランクシャフトトルクを示す";
BA_ "GenSigStartValue" SG_ 428 VSA_REQ_TRQ_1AC 32767;
BA_ "DescriptionE" SG_ 428 VSA_REQ_MSR_PLUS_TRQ "MSR?positive torque request flag";
BA_ "DescriptionJ" SG_ 428 VSA_REQ_MSR_PLUS_TRQ "ＭＳＲプラストルク要求フラグ";
BA_ "ValueTableE" SG_ 428 VSA_REQ_MSR_PLUS_TRQ "1: ?Positive torque requested";
BA_ "DescriptionE" SG_ 428 VSA_TRQ_CONTROL_MODE "Control mode

If the data has remained '3'?for 70 msec, the VSA is judged faulty and no request will be accepted from the VSA?until a reset is performed via IG?operation.";
BA_ "DescriptionJ" SG_ 428 VSA_TRQ_CONTROL_MODE "制御モード

データが '3' が70msec継続した場合、VSA故障と判断し以後IG操作によるﾘｾｯﾄまでVSAからの要求を受け付けない事とする。";
BA_ "ValueTableE" SG_ 428 VSA_TRQ_CONTROL_MODE "0: VSA/TCS control inactive (normal)

1: Request MSR?control

2: Request acceleration control (This value is set when engine control is required)

3: Inhibit VSA/TCS (VSA?failure)";
BA_ "DescriptionE" SG_ 428 VSA_TRQ_DOWN_REQ_FUEL_CUT "Fuel control request signal

ID:?Valid only when the data of 1AAh 2.1-2.0 VSA_TRQ_CONTROL_MODE is '2.'";
BA_ "DescriptionJ" SG_ 428 VSA_TRQ_DOWN_REQ_FUEL_CUT "燃料制御要求信号

ID: 1AAh 2.1-2.0 VSA_TRQ_CONTROL_MODE のデータが '2' の時のみ有効とする。";
BA_ "ValueTableE" SG_ 428 VSA_TRQ_DOWN_REQ_FUEL_CUT "0: No fuel/ignition control (THL?control only)

1: Ignition retard

2: ?All cylinders F/C + Ignition?retard";
BA_ "ValueTableE" SG_ 420 VSA_WARN_STATUS_PUNCTURE "1: ABS control active";
BA_ "ValueTableE" SG_ 420 VSA_WARN_STATUS_DWS "1: ABS control active";
BA_ "ValueTableE" SG_ 420 VSA_ANSWER_DWS_INIT_REQ "1: ABS control active";
BA_ "ValueTableE" SG_ 420 VSA_L_MODE_ABS_EBD "1: ABS, EBD L-MODE";
BA_ "DescriptionE" SG_ 420 VSA_ALIVE_COUNTER_1A4 "Incremented by 1 every time a packet is refreshed.

(0 to 3 ring counters)";
BA_ "DescriptionJ" SG_ 420 VSA_ALIVE_COUNTER_1A4 "1パケット更新毎に1インクリメント

(0～3のリングカウンタ)";
BA_ "ValueTableE" SG_ 420 VSA_ABS_CTRL "1: ABS control active";
BA_ "ValueTableE" SG_ 420 VSA_VSA_CTRL "1: VSA control active";
BA_ "ValueTableE" SG_ 420 VSA_WARN_STATUS_HSA "1: HSA warning is illuminated";
BA_ "DescriptionJ" SG_ 420 VSA_HSA_STATUS_ACT "HSAが作動している状態を示す";
BA_ "DescriptionE" SG_ 420 VSA_ESS_ACT4 "When a head-on collision is detected, '1' is sent with each message which is output 10 times continuously.";
BA_ "DescriptionJ" SG_ 420 VSA_ESS_ACT4 "ABSﾌﾙｻｲｸﾘﾝｸﾞによるESS作動継続ﾌﾗｸﾞ";
BA_ "ValueTableE" SG_ 420 VSA_ESS_ACT4 "0: The continuation of an operation of ESS by ABS full cycle is forbidden.

1: The continuation of an operation of ESS by ABS full cycle is permitted.";
BA_ "DescriptionJ" SG_ 420 VSA_ESS_ACT3 "ABSﾌﾙｻｲｸﾘﾝｸﾞによるESS作動開始ﾌﾗｸﾞ";
BA_ "ValueTableE" SG_ 420 VSA_ESS_ACT3 "0: The operation start of ESS by  ABS full cycle is forbidden.

1: The operation start of ESS by  ABS full cycle is permitted.";
BA_ "DescriptionE" SG_ 420 VSA_REWRITE_START "VSA ECU reprogramming start flag";
BA_ "DescriptionJ" SG_ 420 VSA_REWRITE_START "VSA ECU書換開始フラグ";
BA_ "ValueTableE" SG_ 420 VSA_REWRITE_START "1: Start VSA reprogramming at dealer";
BA_ "ValueTableE" SG_ 420 VSA_BUZZER_STATUS "0: Buzzer OFF

1: Buzzer ON";
BA_ "DescriptionE" SG_ 420 VSA_MID_REQUEST_VSA "VSA MID enlarged warning output flag ";
BA_ "DescriptionJ" SG_ 420 VSA_MID_REQUEST_VSA "VSA MID拡大ワーニング表示許可フラグ";
BA_ "ValueTableE" SG_ 420 VSA_MID_REQUEST_VSA "1: Display VSA MID enlarged warning";
BA_ "ValueTableE" SG_ 420 VSA_LAMP_STATUS_VSA_OFF "1: VSA OFF lamp ON";
BA_ "GenSigStartValue" SG_ 420 VSA_LAMP_STATUS_VSA_OFF 1;
BA_ "ValueTableE" SG_ 420 VSA_WARN_STATUS_VSA "1: VSA warning lamp ON";
BA_ "GenSigStartValue" SG_ 420 VSA_WARN_STATUS_VSA 1;
BA_ "ValueTableE" SG_ 420 VSA_WARN_STATUS_ABS "1: ABS warning lamp ON";
BA_ "GenSigStartValue" SG_ 420 VSA_WARN_STATUS_ABS 1;
BA_ "ValueTableE" SG_ 420 VSA_WARN_STATUS_BRAKE "1: Brake warning lamp ON";
BA_ "GenSigStartValue" SG_ 420 VSA_WARN_STATUS_BRAKE 1;
BA_ "DescriptionE" SG_ 420 VSA_VSA_TCS_ACT "If the TSA?becomes active and the brake lamp turns ON, the bit must be turned 1.";
BA_ "DescriptionJ" SG_ 420 VSA_VSA_TCS_ACT "TSAが作動しﾌﾞﾚｰｷﾗﾝﾌﾟ点灯をする場合はﾋﾞｯﾄを1にすること";
BA_ "ValueTableE" SG_ 420 VSA_VSA_TCS_ACT "1: ?VSA, TCS active";
BA_ "ValueTableE" SG_ 420 VSA_ABS_EBD_ACT "1: ?ABS, EBD active";
BA_ "ValueTableE" SG_ 420 VSA_VSA_TCS_MIL "1: VSA, TCS failure";
BA_ "ValueTableE" SG_ 420 VSA_ABS_EBD_MIL "1: ?ABS, EBD failure";
BA_ "ValueTableE" SG_ 420 VSA_CASEN "1: Permit CAS operation";
BA_ "ValueTableE" SG_ 420 VSA_CAS_ACT "1:  CAS active";
BA_ "ValueTableE" SG_ 420 VSA_BA_ACT "1: BA active ";
BA_ "DescriptionJ" SG_ 420 VSA_MASTER_CYLINDER_PRESSURE "マスターシリンダー液圧

出力固定等の処理がある為、信号出力詳細を確認後使用の事

※NK21Vシステムの場合、LSB等に変更がある為注意すること";
BA_ "ValueTableE" SG_ 420 VSA_MASTER_CYLINDER_PRESSURE "0066: 0kPa

0399: 19623.24kPa";
BA_ "GenSigStartValue" SG_ 420 VSA_MASTER_CYLINDER_PRESSURE 4095;
BA_ "DescriptionJ" SG_ 420 VSA_FAIL_MC_PRESSURE_SENSOR "マスタシリンダ液圧センサ異常フラグ";
BA_ "DescriptionJ" SG_ 420 VSA_INHBIT_MC_PRESSURE_SENSOR "マスタシリンダ液圧センサ一時禁止フラグ";
BA_ "DescriptionJ" SG_ 420 VSA_ESS_ACT2 "減速度によるESS作動継続ﾌﾗｸﾞ";
BA_ "ValueTableE" SG_ 420 VSA_ESS_ACT2 "0: The continuation of an operation of ESS by deceleration is forbidden.

1: The continuation of an operation of ESS by deceleration is permitted.";
BA_ "DescriptionJ" SG_ 420 VSA_ESS_ACT1 "減速度によるESS作動開始ﾌﾗｸﾞ";
BA_ "ValueTableE" SG_ 420 VSA_ESS_ACT1 "0: The operation start of ESS by deceleration is forbidden.

1: The operation start of ESS by deceleration is permitted.";
BA_ "DescriptionJ" SG_ 411 VSA_ALIVE_COUNTER_19B "1パケット更新毎に1インクリメント

(0～3のリングカウンタ)";
BA_ "DescriptionJ" SG_ 411 VSA_ABS_RR_WHEEL_PULSE_COUNTER "右後車輪速パルスカウンタ";
BA_ "DescriptionJ" SG_ 411 VSA_ABS_RL_WHEEL_PULSE_COUNTER "左後車輪速パルスカウンタ";
BA_ "DescriptionJ" SG_ 411 VSA_ABS_FR_WHEEL_PULSE_COUNTER "右前車輪速パルスカウンタ";
BA_ "DescriptionJ" SG_ 411 VSA_ABS_FL_WHEEL_PULSE_COUNTER "左前車輪速パルスカウンタ";
BA_ "DescriptionJ" SG_ 145 VSA_ALIVE_COUNTER_091 "1パケット更新毎に1インクリメント

(0～3のリングカウンタ)";
BA_ "DescriptionE" SG_ 145 VSA_ALIVE_COUNTER_091 "Incremented by 1 every time a packet is refreshed.

(0 to 3 ring counters)";
BA_ "DescriptionE" SG_ 145 VSA_SENSOR_START_UP "During start-up process";
BA_ "DescriptionJ" SG_ 145 VSA_SENSOR_START_UP "起動中";
BA_ "GenSigStartValue" SG_ 145 VSA_SENSOR_START_UP 1;
BA_ "DescriptionE" SG_ 145 VSA_SENSOR_ERR_MC "Abnormal CPU";
BA_ "DescriptionJ" SG_ 145 VSA_SENSOR_ERR_MC "マイコン異常";
BA_ "DescriptionE" SG_ 145 VSA_SENSOR_STATE_IG "Abnormal supply voltage";
BA_ "DescriptionJ" SG_ 145 VSA_SENSOR_STATE_IG "供給電圧(IG)異常";
BA_ "DescriptionJ" SG_ 145 VSA_P_ERR_LON_G "LON_G故障";
BA_ "DescriptionJ" SG_ 145 VSA_P_ERR_LAT_G "LAT_G故障";
BA_ "DescriptionJ" SG_ 145 VSA_P_ERR_DEGC "DegC故障";
BA_ "DescriptionE" SG_ 145 VSA_P_ERR_YAW1 "YAW 1 failure";
BA_ "DescriptionJ" SG_ 145 VSA_P_ERR_YAW1 "YAW1故障";
BA_ "DescriptionJ" SG_ 145 VSA_T_ERR_LON_G "LON_G一時異常";
BA_ "DescriptionJ" SG_ 145 VSA_T_ERR_LAT_G "LAT_G一時異常";
BA_ "DescriptionJ" SG_ 145 VSA_T_ERR_DEGC "DegC一時異常";
BA_ "DescriptionE" SG_ 145 VSA_T_ERR_YAW1 "Temporarily abnormal YAW1";
BA_ "DescriptionJ" SG_ 145 VSA_T_ERR_YAW1 "YAW1一時異常";
BA_ "DescriptionJ" SG_ 145 VSA_LON_G "LON_Gデータ

※出力定義は別表による

※保証範囲はSPECを参照";
BA_ "GenSigStartValue" SG_ 145 VSA_LON_G 512;
BA_ "DescriptionJ" SG_ 145 VSA_LAT_G "LAT_Gデータ

※出力定義は別表による

※保証範囲はSPECを参照";
BA_ "GenSigStartValue" SG_ 145 VSA_LAT_G 512;
BA_ "DescriptionJ" SG_ 145 VSA_DEGC "YAW1温度データ

※出力定義は別表による

※保証範囲はSPECを参照";
BA_ "GenSigStartValue" SG_ 145 VSA_DEGC 103;
BA_ "DescriptionE" SG_ 145 VSA_YAW_1 "YAW1 data

* Refer to the attachment for the definition of the output.

* Refer to SPEC for the guarantee range.";
BA_ "DescriptionJ" SG_ 145 VSA_YAW_1 "YAW1データ

※出力定義は別表による

※保証範囲はSPECを参照";
BA_ "GenSigStartValue" SG_ 145 VSA_YAW_1 512;
VAL_ 422 METER_SW_STATUS_VSA_OFF_1A6 1 "VSA-オフ スイッチ オン  " ;
VAL_ 422 METER_SW_STATUS_PARK_BRAKE_1A6 1 "パーキングブレーキ スイッチ オン" ;
VAL_ 422 METER_SW_STATUS_BRAKE_FLUID_1A6 1 "ブレーキフルード レベル スイッチ オン" ;
VAL_ 1424 VSA_DTC_STORAGE_STATUS 1 "DTC Stored(History or Current)" 0 "DTC Not Stored" ;
VAL_ 426 VSA_SHIFT_REQ_1AA 3 "シフトDOWN要求" 2 "シフトUP要求" 1 "シフトホールド要求" 0 "VSAからのシフト制御要求無し(EATオリジナル制御)" ;
VAL_ 426 VSA_TRQ_DOWN_REQ_FUEL_CUT_1AA 2 "全気筒F/C＋点火リタード" 1 "点火リタード" 0 "燃料/点火制御無し(THL制御のみ)" ;
VAL_ 426 VSA_REQ_MSR_PLUS_TRQ_1AA 1 "プラストルク要求中" ;
VAL_ 426 VSA_TRQ_CONTROL_MODE_1AA 3 "VSA/TCS禁止（VSA故障）" 2 "加速制御要求(エンジン制御が必要な場合にこの値をSETする)" 1 "MSR制御要求" 0 "VSA/TCS非制御中(ノーマル)" ;
VAL_ 316 ENG_CLUTCH_SW_CC_13C 0 "クラッチペダルが踏まれている時（SWがOFF）" 1 "クラッチペダルが踏まれていない時（SWがON）" ;
VAL_ 316 ENG_VSA_ACK1_13C 2 "全気筒F/C" 1 "点火リタード" 0 "燃料/点火制御無し(THL制御のみ)" ;
VAL_ 316 ENG_VSA_PERMIT_PLUS_TRQ_13C 1 "プラストルク許可中" ;
VAL_ 316 ENG_RECEIVE_ERROR_1AA 1 "受信エラーあり" ;
VAL_ 316 ENG_VSA_INHIBIT_VSA_CONTROL_13C 1 "一時的なVSA F/C制御停止" ;
VAL_ 316 ENG_VSA_REFUSED_VSA_CONTROL_13C 1 "VSA制御を拒絶する故障発生中" ;
VAL_ 985 VSA_ABS_DISABLE_EDR 1 "ABS故障中" ;
VAL_ 985 VSA_STABILITY_CTRL1_DISABLE_EDR 1 "STABILITY CONTROL1制御のうち、少なくとも１つ禁止しているとき" 0 "STABILITY CONTROL1制御のうち、すべて禁止していないとき" ;
VAL_ 985 VSA_STABILITY_CTRL2_DISABLE_EDR 1 "STABILITY CONTROL2制御のうち、少なくとも１つ禁止しているとき" 0 "STABILITY CONTROL2制御のうち、すべて禁止していないとき" ;
VAL_ 985 VSA_VSA_EQUIPPED_EDR 1 "VSA装備あり" 0 "VSA装備なし(ABS装備)" ;
VAL_ 985 VSA_ABS_ACT_EDR 1 "ABS作動中" ;
VAL_ 985 VSA_STABILITY_CTRL_ACT_EDR 1 "STABILITY CONTROL作動中" ;
VAL_ 985 VSA_VSA_OFF_STATUS_EDR 1 "VSA OFF 中" ;
VAL_ 808 ENG_STRNNEND 1 "完爆状態" ;
VAL_ 804 ENG_SW_STATUS_SCS 1 "SCSスイッチオン" ;
VAL_ 472 SS30_REQ_PREBRAKE 1 "予圧要求" ;
VAL_ 472 SS30_REQ_BRAKE 1 "減速要求" ;
VAL_ 472 SS30_REQ_BRAKEHOLD 1 "ブレーキ保持要求" ;
VAL_ 472 SS30_STATUS_FAIL 1 "SS30故障" ;
VAL_ 356 METER_SW_STATUS_PARK_BRAKE 1 "パーキングブレーキ スイッチ オン" ;
VAL_ 356 METER_SW_STATUS_BRAKE_FLUID 1 "ブレーキフルード レベル スイッチ オン" ;
VAL_ 356 METER_SW_STATUS_VSA_OFF 1 "VSA-オフ スイッチ オン  " ;
VAL_ 401 CVT_CAS_ON 1 "VSAへのCAS_ON要求" ;
VAL_ 401 CVT_REFUSE_VSA_CONTROL 1 "VSA制御を拒絶するCVT故障発生中" ;
VAL_ 401 CVT_GEAR_POSITION_IND_CVT 15 "Lレンジ制御中" 8 "8th" 7 "7th" 6 "6th" 5 "5th" 4 "4th" 3 "3rd" 2 "2nd" 1 "1st" 0 "オフ" ;
VAL_ 401 CVT_SHFT_IN_PARKING 1 "パーキング" ;
VAL_ 401 CVT_SHFT_IN_REVERSE 1 "リバース" ;
VAL_ 401 CVT_SHFT_IN_NEUTRAL 1 "ニュートラル" ;
VAL_ 401 CVT_SHFT_IN_D 1 "'D'" ;
VAL_ 401 CVT_SHFT_IN_S 1 "'S'" ;
VAL_ 401 CVT_SHFT_IN_L 1 "'L'" ;
VAL_ 380 ENG_IS_PRE_PROGRESS 1 "アイドルストップ実施予告からアイドルストップ復帰予告までを示す" ;
VAL_ 380 ENG_IS_PRE_RESTART 1 "アイドルストップ復帰予告を示す" ;
VAL_ 380 ENG_IS_PROGRESS 1 "アイドルストップ制御開始および進行中を示す" ;
VAL_ 380 ENG_CRUISE_STATUS_CRUISE_LMP 1 "クルーズ制御ランプ点灯" ;
VAL_ 342 STR_ANGLE 32767 "故障時（Invalid）" 7560 "+756[deg]" 0 "0[deg]" 57976 "-756[deg]" ;
VAL_ 304 ENG_NEUTRAL_SENSOR_FAIL 1 "NEUTRAL SENSOR FAIL" ;
VAL_ 304 ENG_RECEIVE_ERROR_1AC 1 "受信エラーあり" ;
VAL_ 304 ENG_SHFT_IN_NEUTRAL 1 "シフトレバーがNEUTRALの位置にあるとき" ;
VAL_ 304 ENG_CLUTCH_SW_CC 0 "クラッチペダルが踏まれている時（SWがOFF）" 1 "クラッチペダルが踏まれていない時（SWがON）" ;
VAL_ 304 ENG_VSA_ACK1 2 "全気筒F/C" 1 "点火リタード" 0 "燃料/点火制御無し(THL制御のみ)" ;
VAL_ 304 ENG_VSA_PERMIT_PLUS_TRQ 1 "プラストルク許可中" ;
VAL_ 304 ENG_VSA_INHIBIT_VSA_CONTROL 1 "一時的なVSA F/C制御停止" ;
VAL_ 304 ENG_VSA_REFUSED_VSA_CONTROL 1 "VSA制御を拒絶する故障発生中" ;
VAL_ 1934 VSA_COMMAND_CODE 5 "Reset of the Calibration" 3 "Calibration" ;
VAL_ 1030 VSA_SPECIFY_CODE_SYS 1 "HMコード" 0 "SAEコード" ;
VAL_ 1030 VSA_DTC_STORAGE 1 "格納" 0 "未格納" ;
VAL_ 490 VSA_MAEPS_REVERSE_F 1 "ﾘﾊﾞｰｽ状態" ;
VAL_ 490 VSA_SYSTEM_F 1 "VSAｼｽﾃﾑ故障" ;
VAL_ 487 VSA_HSA_STATUS_ACT_1E7 1 "作動中" 0 "非作動中" ;
VAL_ 487 VSA_INHBIT_CALIPPER_PRESSURE_FR 1 "キャリパ圧センサFR正常未確定" ;
VAL_ 487 VSA_FAIL_CALIPPER_PRESSURE_FR 1 "キャリパ圧センサFR異常" ;
VAL_ 487 VSA_INHBIT_CALIPPER_PRESSURE_FL 1 "キャリパ圧センサFL正常未確定" ;
VAL_ 487 VSA_FAIL_CALIPPER_PRESSURE_FL 1 "キャリパ圧センサFL異常" ;
VAL_ 432 VSA_INHIBIT_BRAKERELAY 1 "Brakelamprelay temporary disable" ;
VAL_ 432 VSA_INHBIT_LAT_G_SENSOR 1 "LatG sen normalisnotyetconfirm" ;
VAL_ 432 VSA_FAIL_LAT_G_SENSOR 1 "Lateral G sensor failed" ;
VAL_ 432 VSA_ACT_BRAKERELAY 1 "VSA unit activates the BLA" ;
VAL_ 432 VSA_REQ_CVT_TCS 1 "TCS作動許可状態" ;
VAL_ 432 VSA_REQ_CVT_PRS 1 "加圧中" ;
VAL_ 432 VSA_CONTROL_MODE_CVT 3 "予備" 2 "予備" 1 "TCS作動中" 0 "VSA制御可能状態" ;
VAL_ 432 VSA_ABS_STATUS_FR_ABS_EBD_ACT 1 "FR輪ABS、EBD作動中" ;
VAL_ 432 VSA_ABS_STATUS_FL_ABS_EBD_ACT 1 "FL輪ABS、EBD作動中" ;
VAL_ 432 VSA_ABS_STATUS_RR_ABS_EBD_ACT 1 "RR輪ABS、EBD作動中" ;
VAL_ 432 VSA_ABS_STATUS_RL_ABS_EBD_ACT 1 "RL輪ABS、EBD作動中" ;
VAL_ 432 VSA_FAIL_STEERING_SENSOR 1 "舵角センサ異常" ;
VAL_ 432 VSA_FAIL_YAW_RATE_SENSOR 1 "ヨーレイトセンサ異常" ;
VAL_ 432 VSA_FAIL_MC_PRESSURE_SENSOR_1B0 1 "M/C圧センサ異常" ;
VAL_ 432 VSA_ABS_FAIL_FR_VW_SENSOR 1 "車輪速センサFR輪異常" ;
VAL_ 432 VSA_ABS_FAIL_FL_VW_SENSOR 1 "車輪速センサFL輪異常" ;
VAL_ 432 VSA_ABS_FAIL_RR_VW_SENSOR 1 "車輪速センサRR輪異常" ;
VAL_ 432 VSA_ABS_FAIL_RL_VW_SENSOR 1 "車輪速センサRL輪異常" ;
VAL_ 432 VSA_ABS_INHBIT_VW_SENSOR 1 "車輪速センサ正常未確定" ;
VAL_ 432 VSA_ACC_INHIBIT_CVRS_BRAKE 1 "CVRSブレーキ一時禁止" ;
VAL_ 432 VSA_INHBIT_STEERING_SENSOR 1 "舵角センサ正常未確定" ;
VAL_ 432 VSA_ACC_REFUSE_CVRS_BRAKE 1 "CVRSブレーキを拒絶する故障が発生" ;
VAL_ 432 VSA_VW_PULSE_CAPTURED 1 "車輪速パルスあり" ;
VAL_ 432 VSA_INHBIT_YAW_RATE_SENSOR 1 "ヨーレートセンサ正常未確定" 0 "ヨーレートセンサ正常確定" ;
VAL_ 432 VSA_FAIL_BRAKERELAY 1 "BRAKEリレー　故障" ;
VAL_ 432 VSA_SS30_BRAKE_ACT 1 "SS30ブレーキ作動中" ;
VAL_ 428 VSA_IS_SHIFT_INHIBIT_REQUEST 1 "アイドルストップ移行禁止要求中" 0 "通常時" ;
VAL_ 428 VSA_SHIFT_REQ_1AC 3 "シフトDOWN要求" 2 "シフトUP要求" 1 "シフトホールド要求" 0 "VSAからのシフト制御要求無し(EATオリジナル制御)" ;
VAL_ 428 VSA_REQ_MSR_PLUS_TRQ 1 "プラストルク要求中" ;
VAL_ 428 VSA_TRQ_CONTROL_MODE 3 "VSA/TCS禁止（VSA故障）" 2 "加速制御要求(エンジン制御が必要な場合にこの値をSETする)" 1 "MSR制御要求" 0 "VSA/TCS非制御中(ノーマル)" ;
VAL_ 428 VSA_TRQ_DOWN_REQ_FUEL_CUT 2 "全気筒F/C＋点火リタード" 1 "点火リタード" 0 "燃料/点火制御無し(THL制御のみ)" ;
VAL_ 420 VSA_L_MODE_ABS_EBD 1 "ABS,EBD L-MODE中" ;
VAL_ 420 VSA_ABS_CTRL 1 "ABS制御中" ;
VAL_ 420 VSA_VSA_CTRL 1 "VSA制御中" ;
VAL_ 420 VSA_WARN_STATUS_HSA 1 "HSA warning is illuminated" ;
VAL_ 420 VSA_HSA_STATUS_ACT 1 "作動中" 0 "非作動中" ;
VAL_ 420 VSA_ESS_ACT4 1 "ABSﾌﾙｻｲｸﾘﾝｸﾞによるESS作動継続許可" 0 "ABSﾌﾙｻｲｸﾘﾝｸﾞによるESS作動継続禁止" ;
VAL_ 420 VSA_ESS_ACT3 1 "ABSﾌﾙｻｲｸﾘﾝｸﾞによるESS作動開始許可" 0 "ABSﾌﾙｻｲｸﾘﾝｸﾞによるESS作動開始禁止" ;
VAL_ 420 VSA_REWRITE_START 1 "VSA市場書換開始" ;
VAL_ 420 VSA_BUZZER_STATUS 1 "ブザーオン" 0 "ブザーオフ" ;
VAL_ 420 VSA_MID_REQUEST_VSA 1 "VSA MID拡大ワーニング表示許可" ;
VAL_ 420 VSA_LAMP_STATUS_VSA_OFF 1 "VSA　OFFﾗﾝﾌﾟ点灯" ;
VAL_ 420 VSA_WARN_STATUS_VSA 1 "VSA ウォーニングランプ点灯" ;
VAL_ 420 VSA_WARN_STATUS_ABS 1 "ABS ウォーニングランプ点灯" ;
VAL_ 420 VSA_WARN_STATUS_BRAKE 1 "BRAKE ウォーニングランプ点灯" ;
VAL_ 420 VSA_VSA_TCS_ACT 1 "VSA,TCS作動中" ;
VAL_ 420 VSA_ABS_EBD_ACT 1 "ABS,EBD作動中" ;
VAL_ 420 VSA_VSA_TCS_MIL 1 "VSA,TCS故障中" ;
VAL_ 420 VSA_ABS_EBD_MIL 1 "ABS,EBD故障中" ;
VAL_ 420 VSA_CASEN 1 "CAS作動許可" ;
VAL_ 420 VSA_CAS_ACT 1 "CAS作動中" ;
VAL_ 420 VSA_BA_ACT 1 "BA作動中" ;
VAL_ 420 VSA_MASTER_CYLINDER_PRESSURE 921 "19623.24kPa" 102 "0kPa" ;
VAL_ 420 VSA_FAIL_MC_PRESSURE_SENSOR 1 "マスタ圧センサ異常" ;
VAL_ 420 VSA_INHBIT_MC_PRESSURE_SENSOR 1 "マスタ圧センサ正常未確定" ;
VAL_ 420 VSA_ESS_ACT2 1 "減速度によるESS作動継続許可" 0 "減速度によるESS作動継続禁止" ;
VAL_ 420 VSA_ESS_ACT1 1 "減速度によるESS作動開始許可" 0 "減速度によるESS作動開始禁止" ;
VAL_ 145 VSA_SENSOR_START_UP 1 "起動中(センサ出力が保証できない時)" ;
VAL_ 145 VSA_SENSOR_ERR_MC 1 "マイコン及びそれに関わる診断が故障判定した時" ;
VAL_ 145 VSA_SENSOR_STATE_IG 1 "供給電圧(IG)がセンサの機能/性能を守れない時" ;
VAL_ 145 VSA_P_ERR_LON_G 1 "前後G加速度を故障判定した時" ;
VAL_ 145 VSA_P_ERR_LAT_G 1 "横G加速度を故障判定した時" ;
VAL_ 145 VSA_P_ERR_DEGC 1 "ヨーレート1温度データを故障判定した時" ;
VAL_ 145 VSA_P_ERR_YAW1 1 "ヨーレート1を故障判定した時" ;
VAL_ 145 VSA_T_ERR_LON_G 1 "前後G加速度が保証できない時" ;
VAL_ 145 VSA_T_ERR_LAT_G 1 "横G加速度が保証できない時" ;
VAL_ 145 VSA_T_ERR_DEGC 1 "ヨーレート1温度データが保証できない時" ;
VAL_ 145 VSA_T_ERR_YAW1 1 "ヨーレート1が保証できない時" ;
VAL_ 145 VSA_LON_G 1023 "24.5 [m/s2]" 512 "0 [m/s2]" 0 "-24.5 [m/s2]" ;
VAL_ 145 VSA_LAT_G 1023 "24.5 [m/s2]" 512 "0 [m/s2]" 0 "-24.5 [m/s2]" ;
VAL_ 145 VSA_DEGC 255 "+152 [℃]" 128 "+25 [℃]" 0 "-103 [℃]" ;
VAL_ 145 VSA_YAW_1 1023 "125.0 [°/s]" 512 "0 [°/s]" 0 "-125.0 [°/s]" ;
